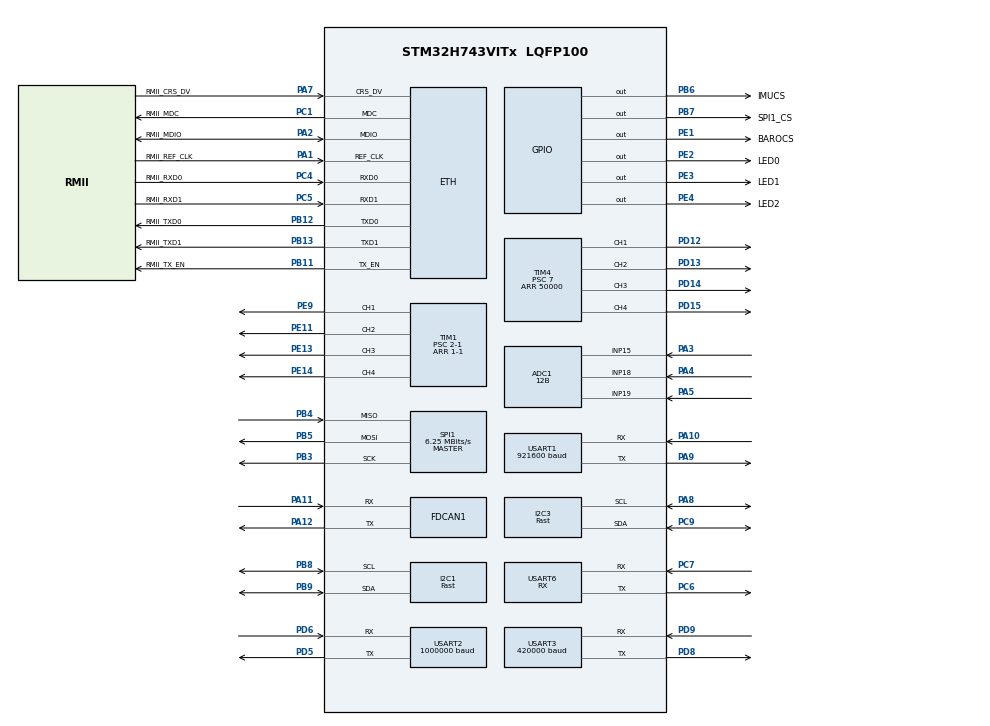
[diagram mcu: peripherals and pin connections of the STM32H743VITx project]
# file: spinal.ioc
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ADC1.Channel-3\#ChannelRegularConversion=ADC_CHANNEL_15
ADC1.NbrOfConversionFlag=1
ADC1.OffsetNumber-3\#ChannelRegularConversion=ADC_OFFSET_NONE
ADC1.OffsetSignedSaturation-3\#ChannelRegularConversion=DISABLE
ADC1.Rank-3\#ChannelRegularConversion=1
ADC1.Resolution=ADC_RESOLUTION_12B
ADC1.SamplingTime-3\#ChannelRegularConversion=ADC_SAMPLETIME_2CYCLES_5
ADC1.master=1
CORTEX_M7.AccessPermission-Cortex_Memory_Protection_Unit_Region0_Settings=MPU_REGION_FULL_ACCESS
CORTEX_M7.AccessPermission-Cortex_Memory_Protection_Unit_Region10_Settings=MPU_REGION_FULL_ACCESS
CORTEX_M7.AccessPermission-Cortex_Memory_Protection_Unit_Region11_Settings=MPU_REGION_FULL_ACCESS
CORTEX_M7.AccessPermission-Cortex_Memory_Protection_Unit_Region1_Settings=MPU_REGION_FULL_ACCESS
CORTEX_M7.AccessPermission-Cortex_Memory_Protection_Unit_Region2_Settings=MPU_REGION_FULL_ACCESS
CORTEX_M7.AccessPermission-Cortex_Memory_Protection_Unit_Region3_Settings=MPU_REGION_FULL_ACCESS
CORTEX_M7.AccessPermission-Cortex_Memory_Protection_Unit_Region4_Settings=MPU_REGION_FULL_ACCESS
CORTEX_M7.AccessPermission-Cortex_Memory_Protection_Unit_Region5_Settings=MPU_REGION_FULL_ACCESS
CORTEX_M7.AccessPermission-Cortex_Memory_Protection_Unit_Region6_Settings=MPU_REGION_FULL_ACCESS
CORTEX_M7.AccessPermission-Cortex_Memory_Protection_Unit_Region7_Settings=MPU_REGION_FULL_ACCESS
CORTEX_M7.AccessPermission-Cortex_Memory_Protection_Unit_Region8_Settings=MPU_REGION_FULL_ACCESS
CORTEX_M7.AccessPermission-Cortex_Memory_Protection_Unit_Region9_Settings=MPU_REGION_FULL_ACCESS
CORTEX_M7.BaseAddress-Cortex_Memory_Protection_Unit_Region0_Settings=0x24040000
CORTEX_M7.BaseAddress-Cortex_Memory_Protection_Unit_Region10_Settings=0x24045100
CORTEX_M7.BaseAddress-Cortex_Memory_Protection_Unit_Region11_Settings=0x24045180
CORTEX_M7.BaseAddress-Cortex_Memory_Protection_Unit_Region1_Settings=0x24040400
CORTEX_M7.BaseAddress-Cortex_Memory_Protection_Unit_Region2_Settings=0x24044400
CORTEX_M7.BaseAddress-Cortex_Memory_Protection_Unit_Region3_Settings=0x30040000
CORTEX_M7.BaseAddress-Cortex_Memory_Protection_Unit_Region4_Settings=0x30044000
CORTEX_M7.BaseAddress-Cortex_Memory_Protection_Unit_Region5_Settings=0x30040000
CORTEX_M7.BaseAddress-Cortex_Memory_Protection_Unit_Region6_Settings=0x24044800
CORTEX_M7.BaseAddress-Cortex_Memory_Protection_Unit_Region7_Settings=0x24044C00
CORTEX_M7.BaseAddress-Cortex_Memory_Protection_Unit_Region8_Settings=0x24045000
CORTEX_M7.BaseAddress-Cortex_Memory_Protection_Unit_Region9_Settings=0x24045080
CORTEX_M7.CPU_DCache=Enabled
CORTEX_M7.CPU_ICache=Enabled
CORTEX_M7.Enable-Cortex_Memory_Protection_Unit_Region0_Settings=MPU_REGION_ENABLE
CORTEX_M7.Enable-Cortex_Memory_Protection_Unit_Region10_Settings=MPU_REGION_ENABLE
CORTEX_M7.Enable-Cortex_Memory_Protection_Unit_Region11_Settings=MPU_REGION_ENABLE
CORTEX_M7.Enable-Cortex_Memory_Protection_Unit_Region1_Settings=MPU_REGION_ENABLE
CORTEX_M7.Enable-Cortex_Memory_Protection_Unit_Region2_Settings=MPU_REGION_ENABLE
CORTEX_M7.Enable-Cortex_Memory_Protection_Unit_Region3_Settings=MPU_REGION_ENABLE
CORTEX_M7.Enable-Cortex_Memory_Protection_Unit_Region4_Settings=MPU_REGION_ENABLE
CORTEX_M7.Enable-Cortex_Memory_Protection_Unit_Region5_Settings=MPU_REGION_ENABLE
CORTEX_M7.Enable-Cortex_Memory_Protection_Unit_Region6_Settings=MPU_REGION_ENABLE
CORTEX_M7.Enable-Cortex_Memory_Protection_Unit_Region7_Settings=MPU_REGION_ENABLE
CORTEX_M7.Enable-Cortex_Memory_Protection_Unit_Region8_Settings=MPU_REGION_ENABLE
CORTEX_M7.Enable-Cortex_Memory_Protection_Unit_Region9_Settings=MPU_REGION_ENABLE
CORTEX_M7.IsBufferable-Cortex_Memory_Protection_Unit_Region10_Settings=MPU_ACCESS_NOT_BUFFERABLE
CORTEX_M7.IsBufferable-Cortex_Memory_Protection_Unit_Region5_Settings=MPU_ACCESS_BUFFERABLE
CORTEX_M7.IsCacheable-Cortex_Memory_Protection_Unit_Region10_Settings=MPU_ACCESS_NOT_CACHEABLE
CORTEX_M7.IsCacheable-Cortex_Memory_Protection_Unit_Region1_Settings=MPU_ACCESS_CACHEABLE
CORTEX_M7.IsCacheable-Cortex_Memory_Protection_Unit_Region4_Settings=MPU_ACCESS_CACHEABLE
CORTEX_M7.IsShareable-Cortex_Memory_Protection_Unit_Region10_Settings=MPU_ACCESS_NOT_SHAREABLE
CORTEX_M7.IsShareable-Cortex_Memory_Protection_Unit_Region1_Settings=MPU_ACCESS_SHAREABLE
CORTEX_M7.MPU_Control=MPU_PRIVILEGED_DEFAULT
CORTEX_M7.Size-Cortex_Memory_Protection_Unit_Region0_Settings=MPU_REGION_SIZE_1KB
CORTEX_M7.Size-Cortex_Memory_Protection_Unit_Region10_Settings=MPU_REGION_SIZE_128B
CORTEX_M7.Size-Cortex_Memory_Protection_Unit_Region11_Settings=MPU_REGION_SIZE_128B
CORTEX_M7.Size-Cortex_Memory_Protection_Unit_Region1_Settings=MPU_REGION_SIZE_16KB
CORTEX_M7.Size-Cortex_Memory_Protection_Unit_Region2_Settings=MPU_REGION_SIZE_16KB
CORTEX_M7.Size-Cortex_Memory_Protection_Unit_Region3_Settings=MPU_REGION_SIZE_16KB
CORTEX_M7.Size-Cortex_Memory_Protection_Unit_Region4_Settings=MPU_REGION_SIZE_16KB
CORTEX_M7.Size-Cortex_Memory_Protection_Unit_Region5_Settings=MPU_REGION_SIZE_256B
CORTEX_M7.Size-Cortex_Memory_Protection_Unit_Region6_Settings=MPU_REGION_SIZE_1KB
CORTEX_M7.Size-Cortex_Memory_Protection_Unit_Region7_Settings=MPU_REGION_SIZE_1KB
CORTEX_M7.Size-Cortex_Memory_Protection_Unit_Region8_Settings=MPU_REGION_SIZE_128B
CORTEX_M7.Size-Cortex_Memory_Protection_Unit_Region9_Settings=MPU_REGION_SIZE_128B
CORTEX_M7.TypeExtField-Cortex_Memory_Protection_Unit_Region0_Settings=MPU_TEX_LEVEL1
CORTEX_M7.TypeExtField-Cortex_Memory_Protection_Unit_Region2_Settings=MPU_TEX_LEVEL1
CORTEX_M7.TypeExtField-Cortex_Memory_Protection_Unit_Region3_Settings=MPU_TEX_LEVEL1
CORTEX_M7.TypeExtField-Cortex_Memory_Protection_Unit_Region6_Settings=MPU_TEX_LEVEL1
CORTEX_M7.TypeExtField-Cortex_Memory_Protection_Unit_Region7_Settings=MPU_TEX_LEVEL1
Dma.Request0=USART1_RX
Dma.Request1=USART1_TX
Dma.Request2=USART3_RX
Dma.Request3=TIM1_CH1
Dma.Request4=TIM1_CH2
Dma.Request5=TIM1_CH3
Dma.Request6=TIM1_CH4
Dma.Request7=USART6_RX
Dma.Request8=USART2_RX
Dma.TIM1_CH1.3.Direction=DMA_MEMORY_TO_PERIPH
Dma.TIM1_CH1.3.EventEnable=DISABLE
Dma.TIM1_CH1.3.FIFOMode=DMA_FIFOMODE_ENABLE
Dma.TIM1_CH1.3.FIFOThreshold=DMA_FIFO_THRESHOLD_1QUARTERFULL
Dma.TIM1_CH1.3.Instance=DMA2_Stream0
Dma.TIM1_CH1.3.MemBurst=DMA_MBURST_SINGLE
Dma.TIM1_CH1.3.MemDataAlignment=DMA_MDATAALIGN_WORD
Dma.TIM1_CH1.3.MemInc=DMA_MINC_ENABLE
Dma.TIM1_CH1.3.Mode=DMA_NORMAL
Dma.TIM1_CH1.3.PeriphBurst=DMA_PBURST_SINGLE
Dma.TIM1_CH1.3.PeriphDataAlignment=DMA_PDATAALIGN_WORD
Dma.TIM1_CH1.3.PeriphInc=DMA_PINC_DISABLE
Dma.TIM1_CH1.3.Polarity=HAL_DMAMUX_REQ_GEN_RISING
Dma.TIM1_CH1.3.Priority=DMA_PRIORITY_HIGH
Dma.TIM1_CH1.3.RequestNumber=1
Dma.TIM1_CH1.3.SignalID=NONE
Dma.TIM1_CH1.3.SyncEnable=DISABLE
Dma.TIM1_CH1.3.SyncPolarity=HAL_DMAMUX_SYNC_NO_EVENT
Dma.TIM1_CH1.3.SyncRequestNumber=1
Dma.TIM1_CH1.3.SyncSignalID=NONE
Dma.TIM1_CH2.4.Direction=DMA_MEMORY_TO_PERIPH
Dma.TIM1_CH2.4.EventEnable=DISABLE
Dma.TIM1_CH2.4.FIFOMode=DMA_FIFOMODE_ENABLE
Dma.TIM1_CH2.4.FIFOThreshold=DMA_FIFO_THRESHOLD_1QUARTERFULL
Dma.TIM1_CH2.4.Instance=DMA2_Stream1
Dma.TIM1_CH2.4.MemBurst=DMA_MBURST_SINGLE
Dma.TIM1_CH2.4.MemDataAlignment=DMA_MDATAALIGN_WORD
Dma.TIM1_CH2.4.MemInc=DMA_MINC_ENABLE
Dma.TIM1_CH2.4.Mode=DMA_NORMAL
Dma.TIM1_CH2.4.PeriphBurst=DMA_PBURST_SINGLE
Dma.TIM1_CH2.4.PeriphDataAlignment=DMA_PDATAALIGN_WORD
Dma.TIM1_CH2.4.PeriphInc=DMA_PINC_DISABLE
Dma.TIM1_CH2.4.Polarity=HAL_DMAMUX_REQ_GEN_RISING
Dma.TIM1_CH2.4.Priority=DMA_PRIORITY_HIGH
Dma.TIM1_CH2.4.RequestNumber=1
Dma.TIM1_CH2.4.SignalID=NONE
Dma.TIM1_CH2.4.SyncEnable=DISABLE
Dma.TIM1_CH2.4.SyncPolarity=HAL_DMAMUX_SYNC_NO_EVENT
Dma.TIM1_CH2.4.SyncRequestNumber=1
Dma.TIM1_CH2.4.SyncSignalID=NONE
Dma.TIM1_CH3.5.Direction=DMA_MEMORY_TO_PERIPH
Dma.TIM1_CH3.5.EventEnable=DISABLE
Dma.TIM1_CH3.5.FIFOMode=DMA_FIFOMODE_ENABLE
Dma.TIM1_CH3.5.FIFOThreshold=DMA_FIFO_THRESHOLD_1QUARTERFULL
Dma.TIM1_CH3.5.Instance=DMA2_Stream2
Dma.TIM1_CH3.5.MemBurst=DMA_MBURST_SINGLE
Dma.TIM1_CH3.5.MemDataAlignment=DMA_MDATAALIGN_WORD
Dma.TIM1_CH3.5.MemInc=DMA_MINC_ENABLE
Dma.TIM1_CH3.5.Mode=DMA_NORMAL
Dma.TIM1_CH3.5.PeriphBurst=DMA_PBURST_SINGLE
Dma.TIM1_CH3.5.PeriphDataAlignment=DMA_PDATAALIGN_WORD
Dma.TIM1_CH3.5.PeriphInc=DMA_PINC_DISABLE
Dma.TIM1_CH3.5.Polarity=HAL_DMAMUX_REQ_GEN_RISING
Dma.TIM1_CH3.5.Priority=DMA_PRIORITY_HIGH
Dma.TIM1_CH3.5.RequestNumber=1
Dma.TIM1_CH3.5.SignalID=NONE
Dma.TIM1_CH3.5.SyncEnable=DISABLE
Dma.TIM1_CH3.5.SyncPolarity=HAL_DMAMUX_SYNC_NO_EVENT
Dma.TIM1_CH3.5.SyncRequestNumber=1
Dma.TIM1_CH3.5.SyncSignalID=NONE
Dma.TIM1_CH4.6.Direction=DMA_MEMORY_TO_PERIPH
Dma.TIM1_CH4.6.EventEnable=DISABLE
Dma.TIM1_CH4.6.FIFOMode=DMA_FIFOMODE_ENABLE
Dma.TIM1_CH4.6.FIFOThreshold=DMA_FIFO_THRESHOLD_1QUARTERFULL
Dma.TIM1_CH4.6.Instance=DMA2_Stream3
Dma.TIM1_CH4.6.MemBurst=DMA_MBURST_SINGLE
Dma.TIM1_CH4.6.MemDataAlignment=DMA_MDATAALIGN_WORD
Dma.TIM1_CH4.6.MemInc=DMA_MINC_ENABLE
Dma.TIM1_CH4.6.Mode=DMA_NORMAL
Dma.TIM1_CH4.6.PeriphBurst=DMA_PBURST_SINGLE
Dma.TIM1_CH4.6.PeriphDataAlignment=DMA_PDATAALIGN_WORD
Dma.TIM1_CH4.6.PeriphInc=DMA_PINC_DISABLE
Dma.TIM1_CH4.6.Polarity=HAL_DMAMUX_REQ_GEN_RISING
Dma.TIM1_CH4.6.Priority=DMA_PRIORITY_HIGH
Dma.TIM1_CH4.6.RequestNumber=1
Dma.TIM1_CH4.6.SignalID=NONE
Dma.TIM1_CH4.6.SyncEnable=DISABLE
Dma.TIM1_CH4.6.SyncPolarity=HAL_DMAMUX_SYNC_NO_EVENT
Dma.TIM1_CH4.6.SyncRequestNumber=1
Dma.TIM1_CH4.6.SyncSignalID=NONE
Dma.USART1_RX.0.Direction=DMA_PERIPH_TO_MEMORY
Dma.USART1_RX.0.EventEnable=DISABLE
Dma.USART1_RX.0.FIFOMode=DMA_FIFOMODE_DISABLE
Dma.USART1_RX.0.Instance=DMA1_Stream0
Dma.USART1_RX.0.MemDataAlignment=DMA_MDATAALIGN_BYTE
Dma.USART1_RX.0.MemInc=DMA_MINC_ENABLE
Dma.USART1_RX.0.Mode=DMA_CIRCULAR
Dma.USART1_RX.0.PeriphDataAlignment=DMA_PDATAALIGN_BYTE
Dma.USART1_RX.0.PeriphInc=DMA_PINC_DISABLE
Dma.USART1_RX.0.Polarity=HAL_DMAMUX_REQ_GEN_RISING
Dma.USART1_RX.0.Priority=DMA_PRIORITY_VERY_HIGH
Dma.USART1_RX.0.RequestNumber=1
Dma.USART1_RX.0.SignalID=NONE
Dma.USART1_RX.0.SyncEnable=DISABLE
Dma.USART1_RX.0.SyncPolarity=HAL_DMAMUX_SYNC_NO_EVENT
Dma.USART1_RX.0.SyncRequestNumber=1
Dma.USART1_RX.0.SyncSignalID=NONE
Dma.USART1_TX.1.Direction=DMA_MEMORY_TO_PERIPH
Dma.USART1_TX.1.EventEnable=DISABLE
Dma.USART1_TX.1.FIFOMode=DMA_FIFOMODE_DISABLE
Dma.USART1_TX.1.Instance=DMA1_Stream1
Dma.USART1_TX.1.MemDataAlignment=DMA_MDATAALIGN_BYTE
Dma.USART1_TX.1.MemInc=DMA_MINC_ENABLE
Dma.USART1_TX.1.Mode=DMA_NORMAL
Dma.USART1_TX.1.PeriphDataAlignment=DMA_PDATAALIGN_BYTE
Dma.USART1_TX.1.PeriphInc=DMA_PINC_DISABLE
Dma.USART1_TX.1.Polarity=HAL_DMAMUX_REQ_GEN_RISING
Dma.USART1_TX.1.Priority=DMA_PRIORITY_VERY_HIGH
Dma.USART1_TX.1.RequestNumber=1
Dma.USART1_TX.1.SignalID=NONE
Dma.USART1_TX.1.SyncEnable=DISABLE
Dma.USART1_TX.1.SyncPolarity=HAL_DMAMUX_SYNC_NO_EVENT
Dma.USART1_TX.1.SyncRequestNumber=1
Dma.USART1_TX.1.SyncSignalID=NONE
Dma.USART2_RX.8.Direction=DMA_PERIPH_TO_MEMORY
Dma.USART2_RX.8.EventEnable=DISABLE
Dma.USART2_RX.8.FIFOMode=DMA_FIFOMODE_DISABLE
Dma.USART2_RX.8.Instance=DMA1_Stream4
Dma.USART2_RX.8.MemDataAlignment=DMA_MDATAALIGN_BYTE
Dma.USART2_RX.8.MemInc=DMA_MINC_ENABLE
Dma.USART2_RX.8.Mode=DMA_CIRCULAR
Dma.USART2_RX.8.PeriphDataAlignment=DMA_PDATAALIGN_BYTE
Dma.USART2_RX.8.PeriphInc=DMA_PINC_DISABLE
Dma.USART2_RX.8.Polarity=HAL_DMAMUX_REQ_GEN_RISING
Dma.USART2_RX.8.Priority=DMA_PRIORITY_HIGH
Dma.USART2_RX.8.RequestNumber=1
Dma.USART2_RX.8.SignalID=NONE
Dma.USART2_RX.8.SyncEnable=DISABLE
Dma.USART2_RX.8.SyncPolarity=HAL_DMAMUX_SYNC_NO_EVENT
Dma.USART2_RX.8.SyncRequestNumber=1
Dma.USART2_RX.8.SyncSignalID=NONE
Dma.USART3_RX.2.Direction=DMA_PERIPH_TO_MEMORY
Dma.USART3_RX.2.EventEnable=DISABLE
Dma.USART3_RX.2.FIFOMode=DMA_FIFOMODE_DISABLE
Dma.USART3_RX.2.Instance=DMA1_Stream2
Dma.USART3_RX.2.MemDataAlignment=DMA_MDATAALIGN_BYTE
Dma.USART3_RX.2.MemInc=DMA_MINC_ENABLE
Dma.USART3_RX.2.Mode=DMA_CIRCULAR
Dma.USART3_RX.2.PeriphDataAlignment=DMA_PDATAALIGN_BYTE
Dma.USART3_RX.2.PeriphInc=DMA_PINC_DISABLE
Dma.USART3_RX.2.Polarity=HAL_DMAMUX_REQ_GEN_RISING
Dma.USART3_RX.2.Priority=DMA_PRIORITY_HIGH
Dma.USART3_RX.2.RequestNumber=1
Dma.USART3_RX.2.SignalID=NONE
Dma.USART3_RX.2.SyncEnable=DISABLE
Dma.USART3_RX.2.SyncPolarity=HAL_DMAMUX_SYNC_NO_EVENT
Dma.USART3_RX.2.SyncRequestNumber=1
Dma.USART3_RX.2.SyncSignalID=NONE
Dma.USART6_RX.7.Direction=DMA_PERIPH_TO_MEMORY
Dma.USART6_RX.7.EventEnable=DISABLE
Dma.USART6_RX.7.FIFOMode=DMA_FIFOMODE_DISABLE
Dma.USART6_RX.7.Instance=DMA1_Stream3
Dma.USART6_RX.7.MemDataAlignment=DMA_MDATAALIGN_BYTE
Dma.USART6_RX.7.MemInc=DMA_MINC_ENABLE
Dma.USART6_RX.7.Mode=DMA_CIRCULAR
Dma.USART6_RX.7.PeriphDataAlignment=DMA_PDATAALIGN_BYTE
Dma.USART6_RX.7.PeriphInc=DMA_PINC_DISABLE
Dma.USART6_RX.7.Polarity=HAL_DMAMUX_REQ_GEN_RISING
Dma.USART6_RX.7.Priority=DMA_PRIORITY_HIGH
Dma.USART6_RX.7.RequestNumber=1
Dma.USART6_RX.7.SignalID=NONE
Dma.USART6_RX.7.SyncEnable=DISABLE
Dma.USART6_RX.7.SyncPolarity=HAL_DMAMUX_SYNC_NO_EVENT
Dma.USART6_RX.7.SyncRequestNumber=1
Dma.USART6_RX.7.SyncSignalID=NONE
ETH.MediaInterface=HAL_ETH_RMII_MODE
FDCAN1.AutoRetransmission=ENABLE
FDCAN1.DataSyncJumpWidth=2
FDCAN1.DataTimeSeg1=7
FDCAN1.DataTimeSeg2=2
FDCAN1.FrameFormat=FDCAN_FRAME_FD_BRS
FDCAN1.MessageRAMOffset=0
FDCAN1.Mode=FDCAN_MODE_NORMAL
FDCAN1.NominalSyncJumpWidth=16
FDCAN1.NominalTimeSeg1=63
FDCAN1.NominalTimeSeg2=16
FDCAN1.RxFifo0ElmtSize=FDCAN_DATA_BYTES_64
FDCAN1.RxFifo0ElmtsNbr=1
FDCAN1.StdFiltersNbr=1
FDCAN1.TxElmtSize=FDCAN_DATA_BYTES_64
FDCAN1.TxFifoQueueElmtsNbr=10
FREERTOS.BinarySemaphores01=coreTaskSem,Dynamic,NULL;uartTxSem,Dynamic,NULL
FREERTOS.Mutexes01=rosPubMutex,Dynamic,NULL;flightControlMutex,Dynamic,NULL
FREERTOS.Tasks01=coreTask,3,1024,coreTaskFunc,Default,NULL,Dynamic,NULL,NULL;rosSpinTask,0,1024,rosSpinTaskFunc,Default,NULL,Dynamic,NULL,NULL;idleTask,-3,128,idleTaskFunc,Default,NULL,Dynamic,NULL,NULL;imuPublishTask,0,1024,imuPublishTaskFunc,Default,NULL,Dynamic,NULL,NULL;voltage,0,256,voltageTask,Default,NULL,Dynamic,NULL,NULL;canRx,3,256,canRxTask,As weak,NULL,Dynamic,NULL,NULL;servoTask,3,256,ServoTaskCallback,As weak,NULL,Dynamic,NULL,NULL
FREERTOS.Timers01=coreTaskTimer,coreTaskEvokeCb,osTimerPeriodic,Default,NULL,Dynamic,NULL
FREERTOS.configTIMER_TASK_PRIORITY=6
FREERTOS.configTOTAL_HEAP_SIZE=25600
FREERTOS.configUSE_TIMERS=1
I2C1.I2C_Speed_Mode=I2C_Fast
I2C1.Timing=0x009034B6
I2C3.I2C_Speed_Mode=I2C_Fast
I2C3.Timing=0x009034B6
LWIP.BSP.number=1
LWIP.GATEWAY_ADDRESS=192.168.025.253
LWIP.IP_ADDRESS=192.168.025.238
LWIP.LWIP_DHCP=0
LWIP.NETMASK_ADDRESS=255.255.255.000
LWIP.Version=v2.1.2_Cube
LWIP0.BSP.STBoard=false
LWIP0.BSP.api=BSP_COMPONENT_DRIVER
LWIP0.BSP.component=LAN8742
LWIP0.BSP.i2caddr=0
LWIP0.BSP.instance=LAN8742
LWIP0.BSP.name=Driver_PHY
LWIP0.BSP.solution=LAN8742
Mcu.Family=STM32H7
Mcu.Name=STM32H743VITx
Mcu.Package=LQFP100
NVIC.DMA1_Stream0_IRQn=true\:5\:0\:false\:false\:true\:true\:false\:true
NVIC.DMA1_Stream1_IRQn=true\:5\:0\:false\:false\:true\:true\:false\:true
NVIC.DMA1_Stream2_IRQn=true\:5\:0\:false\:false\:true\:true\:false\:true
NVIC.DMA1_Stream3_IRQn=true\:5\:0\:false\:false\:true\:true\:false\:true
NVIC.DMA1_Stream4_IRQn=true\:5\:0\:false\:false\:true\:true\:false\:true
NVIC.DMA2_Stream0_IRQn=true\:5\:0\:false\:false\:true\:true\:false\:true
NVIC.DMA2_Stream1_IRQn=true\:5\:0\:false\:false\:true\:false\:false\:true
NVIC.DMA2_Stream2_IRQn=true\:5\:0\:false\:false\:true\:false\:false\:true
NVIC.DMA2_Stream3_IRQn=true\:5\:0\:false\:false\:true\:false\:false\:true
NVIC.ETH_IRQn=true\:5\:0\:false\:false\:true\:true\:true\:true
NVIC.ETH_WKUP_IRQn=true\:5\:0\:false\:false\:true\:true\:true\:true
NVIC.FDCAN1_IT0_IRQn=true\:5\:0\:false\:false\:true\:true\:true\:true
NVIC.PriorityGroup=NVIC_PRIORITYGROUP_4
NVIC.TIM8_BRK_TIM12_IRQn=true\:0\:0\:false\:false\:true\:false\:false\:true
NVIC.TimeBase=TIM8_BRK_TIM12_IRQn
NVIC.TimeBaseIP=TIM12
NVIC.USART1_IRQn=true\:5\:0\:false\:false\:true\:true\:true\:true
PA1.GPIO_Label=RMII_REF_CLK
PA1.GPIO_Speed=GPIO_SPEED_FREQ_VERY_HIGH
PA1.Mode=RMII
PA1.Signal=ETH_REF_CLK
PA10.Mode=Asynchronous
PA10.Signal=USART1_RX
PA11.Mode=FDCAN_Activate
PA11.Signal=FDCAN1_RX
PA12.Mode=FDCAN_Activate
PA12.Signal=FDCAN1_TX
PA13\ (JTMS/SWDIO).Mode=Serial_Wire
PA13\ (JTMS/SWDIO).Signal=DEBUG_JTMS-SWDIO
PA14\ (JTCK/SWCLK).Mode=Serial_Wire
PA14\ (JTCK/SWCLK).Signal=DEBUG_JTCK-SWCLK
PA2.GPIO_Label=RMII_MDIO
PA2.GPIO_Speed=GPIO_SPEED_FREQ_VERY_HIGH
PA2.Mode=RMII
PA2.Signal=ETH_MDIO
PA3.Signal=ADCx_INP15
PA4.Signal=ADCx_INP18
PA5.Signal=ADCx_INP19
PA7.GPIO_Label=RMII_CRS_DV
PA7.GPIO_Speed=GPIO_SPEED_FREQ_VERY_HIGH
PA7.Mode=RMII
PA7.Signal=ETH_CRS_DV
PA8.Mode=I2C
PA8.Signal=I2C3_SCL
PA9.Mode=Asynchronous
PA9.Signal=USART1_TX
PB11.GPIO_Label=RMII_TX_EN
PB11.GPIO_Speed=GPIO_SPEED_FREQ_VERY_HIGH
PB11.Mode=RMII
PB11.Signal=ETH_TX_EN
PB12.GPIO_Label=RMII_TXD0
PB12.GPIO_Speed=GPIO_SPEED_FREQ_VERY_HIGH
PB12.Mode=RMII
PB12.Signal=ETH_TXD0
PB13.GPIO_Label=RMII_TXD1
PB13.GPIO_Speed=GPIO_SPEED_FREQ_VERY_HIGH
PB13.Mode=RMII
PB13.Signal=ETH_TXD1
PB3\ (JTDO/TRACESWO).GPIO_Speed=GPIO_SPEED_FREQ_VERY_HIGH
PB3\ (JTDO/TRACESWO).Mode=Full_Duplex_Master
PB3\ (JTDO/TRACESWO).Signal=SPI1_SCK
PB4\ (NJTRST).GPIO_Speed=GPIO_SPEED_FREQ_VERY_HIGH
PB4\ (NJTRST).Mode=Full_Duplex_Master
PB4\ (NJTRST).Signal=SPI1_MISO
PB5.GPIO_Speed=GPIO_SPEED_FREQ_VERY_HIGH
PB5.Mode=Full_Duplex_Master
PB5.Signal=SPI1_MOSI
PB6.GPIO_FM6=__NULL
PB6.GPIO_Label=IMUCS
PB6.GPIO_Speed=GPIO_SPEED_FREQ_MEDIUM
PB6.PinState=GPIO_PIN_SET
PB6.Signal=GPIO_Output
PB7.GPIO_Label=SPI1_CS
PB7.GPIO_Speed=GPIO_SPEED_FREQ_HIGH
PB7.PinState=GPIO_PIN_SET
PB7.Signal=GPIO_Output
PB8.Mode=I2C
PB8.Signal=I2C1_SCL
PB9.Mode=I2C
PB9.Signal=I2C1_SDA
PC1.GPIO_Label=RMII_MDC
PC1.Mode=RMII
PC1.Signal=ETH_MDC
PC4.GPIO_Label=RMII_RXD0
PC4.GPIO_Speed=GPIO_SPEED_FREQ_VERY_HIGH
PC4.Mode=RMII
PC4.Signal=ETH_RXD0
PC5.GPIO_Label=RMII_RXD1
PC5.GPIO_Speed=GPIO_SPEED_FREQ_VERY_HIGH
PC5.Mode=RMII
PC5.Signal=ETH_RXD1
PC6.Mode=Asynchronous
PC6.Signal=USART6_TX
PC7.Mode=Asynchronous
PC7.Signal=USART6_RX
PC9.Mode=I2C
PC9.Signal=I2C3_SDA
PD12.Signal=S_TIM4_CH1
PD13.Signal=S_TIM4_CH2
PD14.Signal=S_TIM4_CH3
PD15.Signal=S_TIM4_CH4
PD5.GPIO_ModeDefaultOD=GPIO_MODE_AF_PP
PD5.GPIO_PuPd=GPIO_NOPULL
PD5.GPIO_Speed=GPIO_SPEED_FREQ_VERY_HIGH
PD5.Mode=Asynchronous
PD5.Signal=USART2_TX
PD6.Mode=Asynchronous
PD6.Signal=USART2_RX
PD8.GPIO_ModeDefaultOD=GPIO_MODE_AF_PP
PD8.GPIO_PuPd=GPIO_NOPULL
PD8.GPIO_Speed=GPIO_SPEED_FREQ_VERY_HIGH
PD8.Mode=Asynchronous
PD8.Signal=USART3_TX
PD9.Mode=Asynchronous
PD9.Signal=USART3_RX
PE1.GPIO_Label=BAROCS
PE1.Signal=GPIO_Output
PE11.Signal=S_TIM1_CH2
PE13.Signal=S_TIM1_CH3
PE14.Signal=S_TIM1_CH4
PE2.GPIO_Label=LED0
PE2.GPIO_ModeDefaultOutputPP=GPIO_MODE_OUTPUT_OD
PE2.GPIO_Speed=GPIO_SPEED_FREQ_MEDIUM
PE2.Signal=GPIO_Output
PE3.GPIO_Label=LED1
PE3.GPIO_ModeDefaultOutputPP=GPIO_MODE_OUTPUT_OD
PE3.GPIO_PuPd=GPIO_NOPULL
PE3.GPIO_Speed=GPIO_SPEED_FREQ_MEDIUM
PE3.Signal=GPIO_Output
PE4.GPIO_Label=LED2
PE4.GPIO_ModeDefaultOutputPP=GPIO_MODE_OUTPUT_OD
PE4.GPIO_Speed=GPIO_SPEED_FREQ_MEDIUM
PE4.Signal=GPIO_Output
PE9.Signal=S_TIM1_CH1
PH0-OSC_IN\ (PH0).Mode=HSE-External-Oscillator
PH0-OSC_IN\ (PH0).Signal=RCC_OSC_IN
PH1-OSC_OUT\ (PH1).Mode=HSE-External-Oscillator
PH1-OSC_OUT\ (PH1).Signal=RCC_OSC_OUT
ProjectManager.HeapSize=0x2000
ProjectManager.StackSize=0x4000
ProjectManager.TargetToolchain=STM32CubeIDE
RCC.ADCFreq_Value=400000000
RCC.APB1Freq_Value=100000000
RCC.APB2Freq_Value=100000000
RCC.APB3Freq_Value=100000000
RCC.APB4Freq_Value=100000000
RCC.CortexFreq_Value=400000000
RCC.D1PPRE=RCC_APB3_DIV2
RCC.D2PPRE1=RCC_APB1_DIV2
RCC.D2PPRE2=RCC_APB2_DIV2
RCC.D3PPRE=RCC_APB4_DIV2
RCC.DIVM1=1
RCC.DIVM2=1
RCC.DIVM3=1
RCC.DIVN1=100
RCC.DIVN2=100
RCC.DIVN3=100
RCC.DIVQ1=4
RCC.DIVQ2=10
RCC.FDCANCLockSelection=RCC_FDCANCLKSOURCE_PLL2
RCC.HCLKFreq_Value=200000000
RCC.HPRE=RCC_HCLK_DIV2
RCC.HSE_VALUE=8000000
RCC.PLL2FRACN=0
RCC.PLL3FRACN=0
RCC.PLLFRACN=0
RCC.PLLSourceVirtual=RCC_PLLSOURCE_HSE
RCC.PWR_Regulator_Voltage_Scale=PWR_REGULATOR_VOLTAGE_SCALE1
RCC.SYSCLKFreq_VALUE=400000000
RCC.SYSCLKSource=RCC_SYSCLKSOURCE_PLLCLK
RCC.USBFreq_Value=200000000
SH.ADCx_INP15.0=ADC1_INP15,IN15-Single-Ended
SH.ADCx_INP18.0=ADC1_INP18,IN18-Single-Ended
SH.ADCx_INP19.0=ADC1_INP19,IN19-Single-Ended
SH.S_TIM1_CH1.0=TIM1_CH1,PWM Generation1 CH1
SH.S_TIM1_CH2.0=TIM1_CH2,PWM Generation2 CH2
SH.S_TIM1_CH3.0=TIM1_CH3,PWM Generation3 CH3
SH.S_TIM1_CH4.0=TIM1_CH4,PWM Generation4 CH4
SH.S_TIM4_CH1.0=TIM4_CH1,PWM Generation1 CH1
SH.S_TIM4_CH2.0=TIM4_CH2,PWM Generation2 CH2
SH.S_TIM4_CH3.0=TIM4_CH3,PWM Generation3 CH3
SH.S_TIM4_CH4.0=TIM4_CH4,PWM Generation4 CH4
SPI1.BaudRatePrescaler=SPI_BAUDRATEPRESCALER_32
SPI1.CLKPhase=SPI_PHASE_2EDGE
SPI1.CLKPolarity=SPI_POLARITY_HIGH
SPI1.CalculateBaudRate=6.25 MBits/s
SPI1.DataSize=SPI_DATASIZE_8BIT
SPI1.Direction=SPI_DIRECTION_2LINES
SPI1.Mode=SPI_MODE_MASTER
SPI1.VirtualType=VM_MASTER
TIM1.Channel-PWM\ Generation1\ CH1=TIM_CHANNEL_1
TIM1.Channel-PWM\ Generation2\ CH2=TIM_CHANNEL_2
TIM1.Channel-PWM\ Generation3\ CH3=TIM_CHANNEL_3
TIM1.Channel-PWM\ Generation4\ CH4=TIM_CHANNEL_4
TIM1.CounterMode=TIM_COUNTERMODE_UP
TIM1.Period=1-1
TIM1.Prescaler=2-1
TIM1.Pulse-PWM\ Generation1\ CH1=0
TIM4.Channel-PWM\ Generation1\ CH1=TIM_CHANNEL_1
TIM4.Channel-PWM\ Generation2\ CH2=TIM_CHANNEL_2
TIM4.Channel-PWM\ Generation3\ CH3=TIM_CHANNEL_3
TIM4.Channel-PWM\ Generation4\ CH4=TIM_CHANNEL_4
TIM4.Period=50000
TIM4.Prescaler=7
TIM4.Pulse-PWM\ Generation1\ CH1=10000
TIM4.Pulse-PWM\ Generation2\ CH2=10000
TIM4.Pulse-PWM\ Generation3\ CH3=10000
TIM4.Pulse-PWM\ Generation4\ CH4=10000
USART1.BaudRate=921600
USART1.VirtualMode-Asynchronous=VM_ASYNC
USART2.BaudRate=1000000
USART2.Parity=PARITY_NONE
USART2.VirtualMode-Asynchronous=VM_ASYNC
USART2.WordLength=WORDLENGTH_8B
USART3.BaudRate=420000
USART3.Parity=PARITY_NONE
USART3.VirtualMode-Asynchronous=VM_ASYNC
USART3.WordLength=WORDLENGTH_8B
USART6.Mode=MODE_RX
USART6.VirtualMode=VM_ASYNC
VP_FREERTOS_VS_CMSIS_V1.Mode=CMSIS_V1
VP_LWIP_VS_Enabled.Mode=Enabled
VP_SYS_VS_tim12.Mode=TIM12
VP_TIM1_VS_ClockSourceINT.Mode=Internal
VP_TIM4_VS_ClockSourceINT.Mode=Internal
board=custom

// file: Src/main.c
/* USER CODE BEGIN Header */
/**
  ******************************************************************************
  * @file           : main.c
  * @brief          : Main program body
  ******************************************************************************
  * @attention
  *
  * <h2><center>&copy; Copyright (c) 2021 STMicroelectronics.
  * All rights reserved.</center></h2>
  *
  * This software component is licensed by ST under BSD 3-Clause license,
  * the "License"; You may not use this file except in compliance with the
  * License. You may obtain a copy of the License at:
  *                        opensource.org/licenses/BSD-3-Clause
  *
  ******************************************************************************
  */
/* USER CODE END Header */
#include "main.h"
#include "cmsis_os.h"
#include "lwip.h"

/* USER CODE BEGIN Includes */

#include <cstring>
#include <string>

#include "communication/spinal_link_xrce_adapter.h"
#include "xrce_dds/xrce_dds_client.h"
#include "flashmemory/application_capabilities.h"
#include "flashmemory/config_flash_database.h"
#include "flashmemory/config_flash_storage.h"
#include "flashmemory/flashmemory.h"
#include "sensors/imu/drivers/mpu9250/imu_mpu9250.h"
#include "sensors/imu/drivers/icm20948/icm_20948.h"
#include "sensors/baro/baro_ms5611.h"
#include "sensors/gps/gps_ublox.h"
#include "rc/crsf_input.h"
#include "rc/crsf_stm32_uart_transport.h"

#include "battery_status/battery_status.h"
#include "servo/servo.h"
#include "thruster/board/thruster_manager.h"
#include "flight_control/flight_control.h"
#include "bootloader/system_bootloader.h"

#include "state_estimate/state_estimate.h"

/* #include <Spine/spine.h> */

/* #include "dshot_esc/dshot.h" */

/* USER CODE END Includes */

ADC_HandleTypeDef hadc1;

FDCAN_HandleTypeDef hfdcan1;

I2C_HandleTypeDef hi2c1;
I2C_HandleTypeDef hi2c3;

SPI_HandleTypeDef hspi1;

TIM_HandleTypeDef htim1;
TIM_HandleTypeDef htim4;
DMA_HandleTypeDef hdma_tim1_ch1;
DMA_HandleTypeDef hdma_tim1_ch2;
DMA_HandleTypeDef hdma_tim1_ch3;
DMA_HandleTypeDef hdma_tim1_ch4;

UART_HandleTypeDef huart1;
UART_HandleTypeDef huart2;
UART_HandleTypeDef huart3;
UART_HandleTypeDef huart6;
DMA_HandleTypeDef hdma_usart1_rx;
DMA_HandleTypeDef hdma_usart1_tx;
DMA_HandleTypeDef hdma_usart2_rx;
DMA_HandleTypeDef hdma_usart3_rx;
DMA_HandleTypeDef hdma_usart6_rx;

osThreadId coreTaskHandle;
osThreadId communicationTaskHandle;
osThreadId idleTaskHandle;
osThreadId imuPublishTaskHandle;
osThreadId voltageHandle;
osThreadId canRxHandle;
osThreadId servoTaskHandle;
osTimerId coreTaskTimerHandle;
osMutexId rosPubMutexHandle;
osMutexId flightControlMutexHandle;
osSemaphoreId coreTaskSemHandle;
osSemaphoreId uartTxSemHandle;
/* USER CODE BEGIN PV */
osMailQId canMsgMailHandle;

ConfigFlashPayload g_boot_config = ApplicationCapability::defaults();
uint8_t g_uart3_driver = DEFAULT_UART3_DRIVER;
ConfigFlashDatabase config_flash_database_;

/* /\* sensor instances *\/ */
IMUOnboard mpu9250_imu_;
ICM20948 icm20948_imu_;
IMU* imu_ = nullptr;

Baro baro_;
GPS gps_;
CrsfStm32UartTransport crsf_transport_;
CrsfFlightControlSink crsf_control_sink_;
CrsfInput crsf_input_;
BatteryStatus battery_status_;
ThrusterManager thruster_;
FlightControl flight_control_;

/* servo instance */
DirectServo servo_;
/* DShot dshot_; */

StateEstimate estimator_;
XrceDdsClient xrce_client_;
SpinalLinkXrceAdapter spinal_link_xrce_adapter_;

/* USER CODE END PV */

void SystemClock_Config(void);
static void MPU_Config(void);
static void MX_GPIO_Init(void);
static void MX_DMA_Init(void);
static void MX_FDCAN1_Init(void);
static void MX_I2C1_Init(void);
static void MX_SPI1_Init(void);
static void MX_ADC1_Init(void);
static void MX_I2C3_Init(void);
static void MX_USART1_UART_Init(void);
static void MX_USART3_UART_Init(void);
static void MX_TIM1_Init(void);
static void MX_TIM4_Init(void);
static void MX_USART6_UART_Init(void);
static void MX_USART2_UART_Init(void);
void coreTaskFunc(void const * argument);
void communicationTaskFunc(void const * argument);
void idleTaskFunc(void const * argument);
void imuPublishTaskFunc(void const * argument);
void voltageTask(void const * argument);
void canRxTask(void const * argument);
void ServoTaskCallback(void const * argument);
void coreTaskEvokeCb(void const * argument);

int main(void)
{

  /* MPU Configuration--------------------------------------------------------*/
  MPU_Config();

  /* Enable I-Cache---------------------------------------------------------*/
  SCB_EnableICache();

  /* Enable D-Cache---------------------------------------------------------*/
  SCB_EnableDCache();

  /* MCU Configuration--------------------------------------------------------*/

  /* Reset of all peripherals, Initializes the Flash interface and the Systick. */
  HAL_Init();

  /* USER CODE BEGIN Init */

  SystemBootloader::restore_application_boot_address();

  /* USER CODE END Init */

  /* Configure the system clock */
  SystemClock_Config();

  if (!ConfigFlashStorage::load(config_flash_database_))
  {
    config_flash_database_.loadDefaults(ApplicationCapability::defaults());
  }
  g_boot_config = config_flash_database_.activeConfiguration();
  if (!ConfigFlashDatabase::validateConfiguration(g_boot_config, ApplicationCapability::support()))
  {
    g_boot_config = ApplicationCapability::defaults();
  }
  g_uart3_driver = g_boot_config.uart3_driver;
  config_flash_database_.setAppliedConfiguration(g_boot_config);

  /* Initialize all configured peripherals */
  MX_GPIO_Init();
  MX_DMA_Init();
  MX_FDCAN1_Init();
  MX_I2C1_Init();
  MX_SPI1_Init();
  MX_ADC1_Init();
  MX_I2C3_Init();
  MX_USART1_UART_Init();
  if (g_uart3_driver != Uart3Driver::DISABLED) MX_USART3_UART_Init();
  MX_TIM1_Init();
  MX_TIM4_Init();
  MX_USART6_UART_Init();
  MX_USART2_UART_Init();
  /* USER CODE BEGIN 2 */

  // workaround for the wired generation of STMCubeMX
  HAL_NVIC_DisableIRQ(DMA1_Stream0_IRQn); // we do not need DMA Interrupt for USART1 RX, circular mode
  HAL_NVIC_DisableIRQ(DMA1_Stream2_IRQn); // we do not need DMA Interrupt for USART3 RX, circular mode

  /* Flash Memory */
  FlashMemory::init(0x081E0000, FLASH_SECTOR_7);
  // Bank2, Sector7: 0x081E 0000 (128KB); https://www.stmcu.jp/download/?dlid=51599_jp
  // BANK1 (with Sector7) cuases the flash failure by STLink from the second time. So we use BANK_2, which is tested OK

  // It semms like the first 64 byte of flashmemory for data is easily to be overwritten by zero, when re-flash the flash memory.
  // A possible reason is the power supply from stlink does not contain 3.3V output.
  // which is the only difference compared with the old version (STM32F7)
  // So, we introduce following dummy data for a workaround to avoid the vanishment of stored data in flash memory.
  uint8_t dummy_data[64];
  memset(dummy_data, 1, 64);
  FlashMemory::addValue(dummy_data, 64);

#if 0 // test flash memory

  uint8_t test_data[128];
  for(int i = 0; i < 128; i++)
    test_data[i] = i;
  FlashMemory::addValue(test_data, 128);

  int32_t test_int = -1234;
  //int32_t test_int;
  FlashMemory::addValue(&test_int, sizeof(test_int));

  float test_float = 1.1f;
  //float test_float;
  FlashMemory::addValue(&test_float, sizeof(test_float));

  /* FlashMemory::erase(); */
  /* FlashMemory::write(); */
  FlashMemory::read();
#endif

  if (g_boot_config.imu_driver == ImuDriver::MPU9250)
  {
    mpu9250_imu_.init(&hspi1, &hi2c3, IMUCS_GPIO_Port, IMUCS_Pin, LED0_GPIO_Port, LED0_Pin);
    imu_ = &mpu9250_imu_;
  }
  else if (g_boot_config.imu_driver == ImuDriver::ICM20948)
  {
    icm20948_imu_.init(&hspi1, &hi2c3, IMUCS_GPIO_Port, IMUCS_Pin, LED0_GPIO_Port, LED0_Pin);
    imu_ = &icm20948_imu_;
  }
  Baro* selected_baro = nullptr;
  if (g_boot_config.barometer_enabled != 0U)
  {
    baro_.init_hw(&hi2c1, BAROCS_GPIO_Port, BAROCS_Pin);
    selected_baro = &baro_;
  }

  GPS* selected_gps = nullptr;

  if (g_uart3_driver == Uart3Driver::GPS)
  {
    gps_.init(&huart3, LED2_GPIO_Port, LED2_Pin);
    selected_gps = &gps_;
  }
  else if (g_uart3_driver == Uart3Driver::CRSF)
  {
    crsf_transport_.init(&huart3);
  }
  estimator_.init(imu_, selected_baro, selected_gps, g_boot_config.attitude_estimation_enabled != 0U,
                  g_boot_config.height_estimation_enabled != 0U,
                  g_boot_config.position_estimation_enabled != 0U);

/*   DShot* dshotptr = nullptr; */
  battery_status_.init(&hadc1, g_boot_config.motor_output_driver != MotorOutputDriver::DRIVER_DSHOT);

  thruster_.init(&htim1, &htim4, g_boot_config.motor_output_driver);
  if (g_boot_config.motor_output_driver == MotorOutputDriver::DRIVER_DSHOT)
    thruster_.initDShotTelemetry(&huart6);
  thruster_.setBatteryStatus(&battery_status_);

/* #if DSHOT */
  /* estimator_.init(&imu_, &baro_, &gps_, &node, &executor);  // imu + baro + gps => att + alt + pos(xy) */
/*   dshot_.init(DSHOT600, &htim1,TIM_CHANNEL_1, &htim1,TIM_CHANNEL_2, &htim1,TIM_CHANNEL_3, &htim1, TIM_CHANNEL_4); */
/*   dshot_.initTelemetry(&huart6); */
/*   dshotptr = &dshot_; */
/* #else */
/*   estimator_.init(&imu_, &baro_, &gps_, &nh_);  // imu + baro + gps => att + alt + pos(xy) */
/* #endif */

  FlashMemory::read(); // battery scale and IMU calib data (including IMU in neurons)

  const bool servo_connect = servo_.init(&huart2, nullptr, g_boot_config.servo_driver);

  // Keep the legacy calibration/servo layout intact and append the versioned
  // flight parameter image after every previously registered flash value.
  FlashMemory::addValue(
    flight_control_.parameterStorageData(),
    flight_control_.parameterStorageSize());
  FlashMemory::read();

  flight_control_.init(&estimator_, &thruster_, servo_connect ? &servo_ : nullptr);
  flight_control_.setEnabled(g_boot_config.flight_control_enabled != 0U);
  if (g_uart3_driver == Uart3Driver::CRSF)
  {
    crsf_control_sink_.init(&flight_control_);
    crsf_input_.init(&crsf_transport_, &crsf_control_sink_);
    crsf_input_.setEnabled(true);
  }

/*   bool nerve_connect = Spine::init(&hfdcan1, &nh_, &estimator_, &controller_, LED1_GPIO_Port, LED1_Pin); */

/*   if(nerve_connect) Spine::useRTOS(&canMsgMailHandle); // use RTOS for CAN in spianl */

  /* USER CODE END 2 */

  /* Create the mutex(es) */
  /* definition and creation of rosPubMutex */
  osMutexDef(rosPubMutex);
  rosPubMutexHandle = osMutexCreate(osMutex(rosPubMutex));

  /* definition and creation of flightControlMutex */
  osMutexDef(flightControlMutex);
  flightControlMutexHandle = osMutexCreate(osMutex(flightControlMutex));

  /* Create the semaphores(s) */
  /* definition and creation of coreTaskSem */
  osSemaphoreDef(coreTaskSem);
  coreTaskSemHandle = osSemaphoreCreate(osSemaphore(coreTaskSem), 1);

  /* definition and creation of uartTxSem */
  osSemaphoreDef(uartTxSem);
  uartTxSemHandle = osSemaphoreCreate(osSemaphore(uartTxSem), 1);

  xrce_client_.configure(&huart1, &rosPubMutexHandle, &uartTxSemHandle);
  spinal_link_xrce_adapter_.init(&xrce_client_, &estimator_, &flight_control_, &battery_status_,
                             g_uart3_driver == Uart3Driver::CRSF ? &crsf_input_ : nullptr,
                             &thruster_, &config_flash_database_,
                             &flightControlMutexHandle);

  /* Create the timer(s) */
  /* definition and creation of coreTaskTimer */
  osTimerDef(coreTaskTimer, coreTaskEvokeCb);
  coreTaskTimerHandle = osTimerCreate(osTimer(coreTaskTimer), osTimerPeriodic, NULL);

  /* USER CODE BEGIN RTOS_QUEUES */
  /* add queues, ... */
  /* add mail queue for CAN RX */
  /* osMailQDef(CanMail, 10, can_msg); // defualt: 20 for 8 data bytes (in case of initializer sendBoardConfig (4 servo: 1 + 4 x 3 = 13 packets)); 10 for 64 data bytes */
  /* canMsgMailHandle = osMailCreate(osMailQ(CanMail), NULL); */

  /* USER CODE END RTOS_QUEUES */

  /* Create the thread(s) */
  /* definition and creation of coreTask */
  osThreadDef(coreTask, coreTaskFunc, osPriorityRealtime, 0, 1024);
  coreTaskHandle = osThreadCreate(osThread(coreTask), NULL);

  /* Definition and creation of the direct XRCE-DDS communication task. */
  osThreadDef(communicationTask, communicationTaskFunc, osPriorityNormal, 0, 2048);
  communicationTaskHandle = osThreadCreate(osThread(communicationTask), NULL);

  /* definition and creation of idleTask */
  osThreadDef(idleTask, idleTaskFunc, osPriorityIdle, 0, 128);
  idleTaskHandle = osThreadCreate(osThread(idleTask), NULL);

  /* definition and creation of voltage */
  osThreadDef(voltage, voltageTask, osPriorityNormal, 0, 256);
  voltageHandle = osThreadCreate(osThread(voltage), NULL);

  /* definition and creation of canRx */
  osThreadDef(canRx, canRxTask, osPriorityRealtime, 0, 256);
  canRxHandle = osThreadCreate(osThread(canRx), NULL);

  /* definition and creation of servoTask */
  osThreadDef(servoTask, ServoTaskCallback, osPriorityRealtime, 0, 256);
  servoTaskHandle = osThreadCreate(osThread(servoTask), NULL);

  /* Start scheduler */
  osKernelStart();

  /* We should never get here as control is now taken by the scheduler */
  /* Infinite loop */
  while (1)
  {

    /* USER CODE BEGIN 3 */
    HAL_GPIO_TogglePin(LED0_GPIO_Port, LED0_Pin);
    HAL_GPIO_TogglePin(LED1_GPIO_Port, LED1_Pin);
    HAL_GPIO_TogglePin(LED2_GPIO_Port, LED2_Pin);
    HAL_Delay(1000);
  }
  /* USER CODE END 3 */
}

void SystemClock_Config(void)
{
  RCC_OscInitTypeDef RCC_OscInitStruct = {0};
  RCC_ClkInitTypeDef RCC_ClkInitStruct = {0};
  RCC_PeriphCLKInitTypeDef PeriphClkInitStruct = {0};

  /** Supply configuration update enable
  */
  HAL_PWREx_ConfigSupply(PWR_LDO_SUPPLY);
  /** Configure the main internal regulator output voltage
  */
  __HAL_PWR_VOLTAGESCALING_CONFIG(PWR_REGULATOR_VOLTAGE_SCALE1);

  while(!__HAL_PWR_GET_FLAG(PWR_FLAG_VOSRDY)) {}
  /** Macro to configure the PLL clock source
  */
  __HAL_RCC_PLL_PLLSOURCE_CONFIG(RCC_PLLSOURCE_HSE);
  /** Initializes the RCC Oscillators according to the specified parameters
  * in the RCC_OscInitTypeDef structure.
  */
  RCC_OscInitStruct.OscillatorType = RCC_OSCILLATORTYPE_HSE;
  RCC_OscInitStruct.HSEState = RCC_HSE_ON;
  RCC_OscInitStruct.PLL.PLLState = RCC_PLL_ON;
  RCC_OscInitStruct.PLL.PLLSource = RCC_PLLSOURCE_HSE;
  RCC_OscInitStruct.PLL.PLLM = 1;
  RCC_OscInitStruct.PLL.PLLN = 100;
  RCC_OscInitStruct.PLL.PLLP = 2;
  RCC_OscInitStruct.PLL.PLLQ = 4;
  RCC_OscInitStruct.PLL.PLLR = 2;
  RCC_OscInitStruct.PLL.PLLRGE = RCC_PLL1VCIRANGE_3;
  RCC_OscInitStruct.PLL.PLLVCOSEL = RCC_PLL1VCOWIDE;
  RCC_OscInitStruct.PLL.PLLFRACN = 0;
  if (HAL_RCC_OscConfig(&RCC_OscInitStruct) != HAL_OK)
  {
    Error_Handler();
  }
  /** Initializes the CPU, AHB and APB buses clocks
  */
  RCC_ClkInitStruct.ClockType = RCC_CLOCKTYPE_HCLK|RCC_CLOCKTYPE_SYSCLK
                              |RCC_CLOCKTYPE_PCLK1|RCC_CLOCKTYPE_PCLK2
                              |RCC_CLOCKTYPE_D3PCLK1|RCC_CLOCKTYPE_D1PCLK1;
  RCC_ClkInitStruct.SYSCLKSource = RCC_SYSCLKSOURCE_PLLCLK;
  RCC_ClkInitStruct.SYSCLKDivider = RCC_SYSCLK_DIV1;
  RCC_ClkInitStruct.AHBCLKDivider = RCC_HCLK_DIV2;
  RCC_ClkInitStruct.APB3CLKDivider = RCC_APB3_DIV2;
  RCC_ClkInitStruct.APB1CLKDivider = RCC_APB1_DIV2;
  RCC_ClkInitStruct.APB2CLKDivider = RCC_APB2_DIV2;
  RCC_ClkInitStruct.APB4CLKDivider = RCC_APB4_DIV2;

  if (HAL_RCC_ClockConfig(&RCC_ClkInitStruct, FLASH_LATENCY_2) != HAL_OK)
  {
    Error_Handler();
  }
  PeriphClkInitStruct.PeriphClockSelection = RCC_PERIPHCLK_USART3|RCC_PERIPHCLK_USART2
                              |RCC_PERIPHCLK_USART6|RCC_PERIPHCLK_FDCAN
                              |RCC_PERIPHCLK_USART1|RCC_PERIPHCLK_SPI1
                              |RCC_PERIPHCLK_I2C3|RCC_PERIPHCLK_ADC
                              |RCC_PERIPHCLK_I2C1;
  PeriphClkInitStruct.PLL2.PLL2M = 1;
  PeriphClkInitStruct.PLL2.PLL2N = 100;
  PeriphClkInitStruct.PLL2.PLL2P = 2;
  PeriphClkInitStruct.PLL2.PLL2Q = 10;
  PeriphClkInitStruct.PLL2.PLL2R = 2;
  PeriphClkInitStruct.PLL2.PLL2RGE = RCC_PLL2VCIRANGE_3;
  PeriphClkInitStruct.PLL2.PLL2VCOSEL = RCC_PLL2VCOWIDE;
  PeriphClkInitStruct.PLL2.PLL2FRACN = 0;
  PeriphClkInitStruct.Spi123ClockSelection = RCC_SPI123CLKSOURCE_PLL;
  PeriphClkInitStruct.FdcanClockSelection = RCC_FDCANCLKSOURCE_PLL2;
  PeriphClkInitStruct.Usart234578ClockSelection = RCC_USART234578CLKSOURCE_D2PCLK1;
  PeriphClkInitStruct.Usart16ClockSelection = RCC_USART16CLKSOURCE_D2PCLK2;
  PeriphClkInitStruct.I2c123ClockSelection = RCC_I2C123CLKSOURCE_D2PCLK1;
  PeriphClkInitStruct.AdcClockSelection = RCC_ADCCLKSOURCE_PLL2;
  if (HAL_RCCEx_PeriphCLKConfig(&PeriphClkInitStruct) != HAL_OK)
  {
    Error_Handler();
  }
}

static void MX_ADC1_Init(void)
{

  ADC_MultiModeTypeDef multimode = {0};
  ADC_ChannelConfTypeDef sConfig = {0};

  /** Common config
  */
  hadc1.Instance = ADC1;
  hadc1.Init.ClockPrescaler = ADC_CLOCK_ASYNC_DIV12;
  hadc1.Init.Resolution = ADC_RESOLUTION_12B;
  hadc1.Init.ScanConvMode = ADC_SCAN_DISABLE;
  hadc1.Init.EOCSelection = ADC_EOC_SINGLE_CONV;
  hadc1.Init.LowPowerAutoWait = DISABLE;
  hadc1.Init.ContinuousConvMode = DISABLE;
  hadc1.Init.NbrOfConversion = 1;
  hadc1.Init.DiscontinuousConvMode = DISABLE;
  hadc1.Init.ExternalTrigConv = ADC_SOFTWARE_START;
  hadc1.Init.ExternalTrigConvEdge = ADC_EXTERNALTRIGCONVEDGE_NONE;
  hadc1.Init.ConversionDataManagement = ADC_CONVERSIONDATA_DR;
  hadc1.Init.Overrun = ADC_OVR_DATA_PRESERVED;
  hadc1.Init.LeftBitShift = ADC_LEFTBITSHIFT_NONE;
  hadc1.Init.OversamplingMode = DISABLE;
  if (HAL_ADC_Init(&hadc1) != HAL_OK)
  {
    Error_Handler();
  }
  /** Configure the ADC multi-mode
  */
  multimode.Mode = ADC_MODE_INDEPENDENT;
  if (HAL_ADCEx_MultiModeConfigChannel(&hadc1, &multimode) != HAL_OK)
  {
    Error_Handler();
  }
  /** Configure Regular Channel
  */
  sConfig.Channel = ADC_CHANNEL_15;
  sConfig.Rank = ADC_REGULAR_RANK_1;
  sConfig.SamplingTime = ADC_SAMPLETIME_2CYCLES_5;
  sConfig.SingleDiff = ADC_SINGLE_ENDED;
  sConfig.OffsetNumber = ADC_OFFSET_NONE;
  sConfig.Offset = 0;
  sConfig.OffsetSignedSaturation = DISABLE;
  if (HAL_ADC_ConfigChannel(&hadc1, &sConfig) != HAL_OK)
  {
    Error_Handler();
  }

}

static void MX_FDCAN1_Init(void)
{

  hfdcan1.Instance = FDCAN1;
  hfdcan1.Init.FrameFormat = FDCAN_FRAME_FD_BRS;
  hfdcan1.Init.Mode = FDCAN_MODE_NORMAL;
  hfdcan1.Init.AutoRetransmission = ENABLE;
  hfdcan1.Init.TransmitPause = DISABLE;
  hfdcan1.Init.ProtocolException = DISABLE;
  hfdcan1.Init.NominalPrescaler = 1;
  hfdcan1.Init.NominalSyncJumpWidth = 16;
  hfdcan1.Init.NominalTimeSeg1 = 63;
  hfdcan1.Init.NominalTimeSeg2 = 16;
  hfdcan1.Init.DataPrescaler = 1;
  hfdcan1.Init.DataSyncJumpWidth = 2;
  hfdcan1.Init.DataTimeSeg1 = 7;
  hfdcan1.Init.DataTimeSeg2 = 2;
  hfdcan1.Init.MessageRAMOffset = 0;
  hfdcan1.Init.StdFiltersNbr = 1;
  hfdcan1.Init.ExtFiltersNbr = 0;
  hfdcan1.Init.RxFifo0ElmtsNbr = 1;
  hfdcan1.Init.RxFifo0ElmtSize = FDCAN_DATA_BYTES_64;
  hfdcan1.Init.RxFifo1ElmtsNbr = 0;
  hfdcan1.Init.RxFifo1ElmtSize = FDCAN_DATA_BYTES_8;
  hfdcan1.Init.RxBuffersNbr = 0;
  hfdcan1.Init.RxBufferSize = FDCAN_DATA_BYTES_8;
  hfdcan1.Init.TxEventsNbr = 0;
  hfdcan1.Init.TxBuffersNbr = 0;
  hfdcan1.Init.TxFifoQueueElmtsNbr = 10;
  hfdcan1.Init.TxFifoQueueMode = FDCAN_TX_FIFO_OPERATION;
  hfdcan1.Init.TxElmtSize = FDCAN_DATA_BYTES_64;
  if (HAL_FDCAN_Init(&hfdcan1) != HAL_OK)
  {
    Error_Handler();
  }

}

static void MX_I2C1_Init(void)
{

  hi2c1.Instance = I2C1;
  hi2c1.Init.Timing = 0x009034B6;
  hi2c1.Init.OwnAddress1 = 0;
  hi2c1.Init.AddressingMode = I2C_ADDRESSINGMODE_7BIT;
  hi2c1.Init.DualAddressMode = I2C_DUALADDRESS_DISABLE;
  hi2c1.Init.OwnAddress2 = 0;
  hi2c1.Init.OwnAddress2Masks = I2C_OA2_NOMASK;
  hi2c1.Init.GeneralCallMode = I2C_GENERALCALL_DISABLE;
  hi2c1.Init.NoStretchMode = I2C_NOSTRETCH_DISABLE;
  if (HAL_I2C_Init(&hi2c1) != HAL_OK)
  {
    Error_Handler();
  }
  /** Configure Analogue filter
  */
  if (HAL_I2CEx_ConfigAnalogFilter(&hi2c1, I2C_ANALOGFILTER_ENABLE) != HAL_OK)
  {
    Error_Handler();
  }
  /** Configure Digital filter
  */
  if (HAL_I2CEx_ConfigDigitalFilter(&hi2c1, 0) != HAL_OK)
  {
    Error_Handler();
  }

}

static void MX_I2C3_Init(void)
{

  hi2c3.Instance = I2C3;
  hi2c3.Init.Timing = 0x009034B6;
  hi2c3.Init.OwnAddress1 = 0;
  hi2c3.Init.AddressingMode = I2C_ADDRESSINGMODE_7BIT;
  hi2c3.Init.DualAddressMode = I2C_DUALADDRESS_DISABLE;
  hi2c3.Init.OwnAddress2 = 0;
  hi2c3.Init.OwnAddress2Masks = I2C_OA2_NOMASK;
  hi2c3.Init.GeneralCallMode = I2C_GENERALCALL_DISABLE;
  hi2c3.Init.NoStretchMode = I2C_NOSTRETCH_DISABLE;
  if (HAL_I2C_Init(&hi2c3) != HAL_OK)
  {
    Error_Handler();
  }
  /** Configure Analogue filter
  */
  if (HAL_I2CEx_ConfigAnalogFilter(&hi2c3, I2C_ANALOGFILTER_ENABLE) != HAL_OK)
  {
    Error_Handler();
  }
  /** Configure Digital filter
  */
  if (HAL_I2CEx_ConfigDigitalFilter(&hi2c3, 0) != HAL_OK)
  {
    Error_Handler();
  }

}

static void MX_SPI1_Init(void)
{

  /* SPI1 parameter configuration*/
  hspi1.Instance = SPI1;
  hspi1.Init.Mode = SPI_MODE_MASTER;
  hspi1.Init.Direction = SPI_DIRECTION_2LINES;
  hspi1.Init.DataSize = SPI_DATASIZE_8BIT;
  hspi1.Init.CLKPolarity = SPI_POLARITY_HIGH;
  hspi1.Init.CLKPhase = SPI_PHASE_2EDGE;
  hspi1.Init.NSS = SPI_NSS_SOFT;
  hspi1.Init.BaudRatePrescaler = SPI_BAUDRATEPRESCALER_32;
  hspi1.Init.FirstBit = SPI_FIRSTBIT_MSB;
  hspi1.Init.TIMode = SPI_TIMODE_DISABLE;
  hspi1.Init.CRCCalculation = SPI_CRCCALCULATION_DISABLE;
  hspi1.Init.CRCPolynomial = 0x0;
  hspi1.Init.NSSPMode = SPI_NSS_PULSE_ENABLE;
  hspi1.Init.NSSPolarity = SPI_NSS_POLARITY_LOW;
  hspi1.Init.FifoThreshold = SPI_FIFO_THRESHOLD_01DATA;
  hspi1.Init.TxCRCInitializationPattern = SPI_CRC_INITIALIZATION_ALL_ZERO_PATTERN;
  hspi1.Init.RxCRCInitializationPattern = SPI_CRC_INITIALIZATION_ALL_ZERO_PATTERN;
  hspi1.Init.MasterSSIdleness = SPI_MASTER_SS_IDLENESS_00CYCLE;
  hspi1.Init.MasterInterDataIdleness = SPI_MASTER_INTERDATA_IDLENESS_00CYCLE;
  hspi1.Init.MasterReceiverAutoSusp = SPI_MASTER_RX_AUTOSUSP_DISABLE;
  hspi1.Init.MasterKeepIOState = SPI_MASTER_KEEP_IO_STATE_DISABLE;
  hspi1.Init.IOSwap = SPI_IO_SWAP_DISABLE;
  if (HAL_SPI_Init(&hspi1) != HAL_OK)
  {
    Error_Handler();
  }

}

static void MX_TIM1_Init(void)
{

  TIM_ClockConfigTypeDef sClockSourceConfig = {0};
  TIM_MasterConfigTypeDef sMasterConfig = {0};
  TIM_OC_InitTypeDef sConfigOC = {0};
  TIM_BreakDeadTimeConfigTypeDef sBreakDeadTimeConfig = {0};

  htim1.Instance = TIM1;
  htim1.Init.Prescaler = 2-1;
  htim1.Init.CounterMode = TIM_COUNTERMODE_UP;
  htim1.Init.Period = 1-1;
  htim1.Init.ClockDivision = TIM_CLOCKDIVISION_DIV1;
  htim1.Init.RepetitionCounter = 0;
  htim1.Init.AutoReloadPreload = TIM_AUTORELOAD_PRELOAD_DISABLE;
  if (HAL_TIM_Base_Init(&htim1) != HAL_OK)
  {
    Error_Handler();
  }
  sClockSourceConfig.ClockSource = TIM_CLOCKSOURCE_INTERNAL;
  if (HAL_TIM_ConfigClockSource(&htim1, &sClockSourceConfig) != HAL_OK)
  {
    Error_Handler();
  }
  if (HAL_TIM_PWM_Init(&htim1) != HAL_OK)
  {
    Error_Handler();
  }
  sMasterConfig.MasterOutputTrigger = TIM_TRGO_RESET;
  sMasterConfig.MasterOutputTrigger2 = TIM_TRGO2_RESET;
  sMasterConfig.MasterSlaveMode = TIM_MASTERSLAVEMODE_DISABLE;
  if (HAL_TIMEx_MasterConfigSynchronization(&htim1, &sMasterConfig) != HAL_OK)
  {
    Error_Handler();
  }
  sConfigOC.OCMode = TIM_OCMODE_PWM1;
  sConfigOC.Pulse = 0;
  sConfigOC.OCPolarity = TIM_OCPOLARITY_HIGH;
  sConfigOC.OCNPolarity = TIM_OCNPOLARITY_HIGH;
  sConfigOC.OCFastMode = TIM_OCFAST_DISABLE;
  sConfigOC.OCIdleState = TIM_OCIDLESTATE_RESET;
  sConfigOC.OCNIdleState = TIM_OCNIDLESTATE_RESET;
  if (HAL_TIM_PWM_ConfigChannel(&htim1, &sConfigOC, TIM_CHANNEL_1) != HAL_OK)
  {
    Error_Handler();
  }
  if (HAL_TIM_PWM_ConfigChannel(&htim1, &sConfigOC, TIM_CHANNEL_2) != HAL_OK)
  {
    Error_Handler();
  }
  if (HAL_TIM_PWM_ConfigChannel(&htim1, &sConfigOC, TIM_CHANNEL_3) != HAL_OK)
  {
    Error_Handler();
  }
  if (HAL_TIM_PWM_ConfigChannel(&htim1, &sConfigOC, TIM_CHANNEL_4) != HAL_OK)
  {
    Error_Handler();
  }
  sBreakDeadTimeConfig.OffStateRunMode = TIM_OSSR_DISABLE;
  sBreakDeadTimeConfig.OffStateIDLEMode = TIM_OSSI_DISABLE;
  sBreakDeadTimeConfig.LockLevel = TIM_LOCKLEVEL_OFF;
  sBreakDeadTimeConfig.DeadTime = 0;
  sBreakDeadTimeConfig.BreakState = TIM_BREAK_DISABLE;
  sBreakDeadTimeConfig.BreakPolarity = TIM_BREAKPOLARITY_HIGH;
  sBreakDeadTimeConfig.BreakFilter = 0;
  sBreakDeadTimeConfig.Break2State = TIM_BREAK2_DISABLE;
  sBreakDeadTimeConfig.Break2Polarity = TIM_BREAK2POLARITY_HIGH;
  sBreakDeadTimeConfig.Break2Filter = 0;
  sBreakDeadTimeConfig.AutomaticOutput = TIM_AUTOMATICOUTPUT_DISABLE;
  if (HAL_TIMEx_ConfigBreakDeadTime(&htim1, &sBreakDeadTimeConfig) != HAL_OK)
  {
    Error_Handler();
  }
  HAL_TIM_MspPostInit(&htim1);

}

static void MX_TIM4_Init(void)
{

  TIM_ClockConfigTypeDef sClockSourceConfig = {0};
  TIM_MasterConfigTypeDef sMasterConfig = {0};
  TIM_OC_InitTypeDef sConfigOC = {0};

  htim4.Instance = TIM4;
  htim4.Init.Prescaler = 7;
  htim4.Init.CounterMode = TIM_COUNTERMODE_UP;
  htim4.Init.Period = 50000;
  htim4.Init.ClockDivision = TIM_CLOCKDIVISION_DIV1;
  htim4.Init.AutoReloadPreload = TIM_AUTORELOAD_PRELOAD_DISABLE;
  if (HAL_TIM_Base_Init(&htim4) != HAL_OK)
  {
    Error_Handler();
  }
  sClockSourceConfig.ClockSource = TIM_CLOCKSOURCE_INTERNAL;
  if (HAL_TIM_ConfigClockSource(&htim4, &sClockSourceConfig) != HAL_OK)
  {
    Error_Handler();
  }
  if (HAL_TIM_PWM_Init(&htim4) != HAL_OK)
  {
    Error_Handler();
  }
  sMasterConfig.MasterOutputTrigger = TIM_TRGO_RESET;
  sMasterConfig.MasterSlaveMode = TIM_MASTERSLAVEMODE_DISABLE;
  if (HAL_TIMEx_MasterConfigSynchronization(&htim4, &sMasterConfig) != HAL_OK)
  {
    Error_Handler();
  }
  sConfigOC.OCMode = TIM_OCMODE_PWM1;
  sConfigOC.Pulse = 10000;
  sConfigOC.OCPolarity = TIM_OCPOLARITY_HIGH;
  sConfigOC.OCFastMode = TIM_OCFAST_DISABLE;
  if (HAL_TIM_PWM_ConfigChannel(&htim4, &sConfigOC, TIM_CHANNEL_1) != HAL_OK)
  {
    Error_Handler();
  }
  if (HAL_TIM_PWM_ConfigChannel(&htim4, &sConfigOC, TIM_CHANNEL_2) != HAL_OK)
  {
    Error_Handler();
  }
  if (HAL_TIM_PWM_ConfigChannel(&htim4, &sConfigOC, TIM_CHANNEL_3) != HAL_OK)
  {
    Error_Handler();
  }
  if (HAL_TIM_PWM_ConfigChannel(&htim4, &sConfigOC, TIM_CHANNEL_4) != HAL_OK)
  {
    Error_Handler();
  }
  HAL_TIM_MspPostInit(&htim4);

}

static void MX_USART1_UART_Init(void)
{

  huart1.Instance = USART1;
  huart1.Init.BaudRate = 921600;
  huart1.Init.WordLength = UART_WORDLENGTH_8B;
  huart1.Init.StopBits = UART_STOPBITS_1;
  huart1.Init.Parity = UART_PARITY_NONE;
  huart1.Init.Mode = UART_MODE_TX_RX;
  huart1.Init.HwFlowCtl = UART_HWCONTROL_NONE;
  huart1.Init.OverSampling = UART_OVERSAMPLING_16;
  huart1.Init.OneBitSampling = UART_ONE_BIT_SAMPLE_DISABLE;
  huart1.Init.ClockPrescaler = UART_PRESCALER_DIV1;
  huart1.AdvancedInit.AdvFeatureInit = UART_ADVFEATURE_NO_INIT;
  if (HAL_UART_Init(&huart1) != HAL_OK)
  {
    Error_Handler();
  }
  if (HAL_UARTEx_SetTxFifoThreshold(&huart1, UART_TXFIFO_THRESHOLD_1_8) != HAL_OK)
  {
    Error_Handler();
  }
  if (HAL_UARTEx_SetRxFifoThreshold(&huart1, UART_RXFIFO_THRESHOLD_1_8) != HAL_OK)
  {
    Error_Handler();
  }
  if (HAL_UARTEx_DisableFifoMode(&huart1) != HAL_OK)
  {
    Error_Handler();
  }

}

static void MX_USART2_UART_Init(void)
{

  huart2.Instance = USART2;
  huart2.Init.BaudRate = 1000000;
  huart2.Init.WordLength = UART_WORDLENGTH_8B;
  huart2.Init.StopBits = UART_STOPBITS_1;
  huart2.Init.Parity = UART_PARITY_NONE;
  huart2.Init.Mode = UART_MODE_TX_RX;
  huart2.Init.HwFlowCtl = UART_HWCONTROL_NONE;
  huart2.Init.OverSampling = UART_OVERSAMPLING_16;
  huart2.Init.OneBitSampling = UART_ONE_BIT_SAMPLE_DISABLE;
  huart2.Init.ClockPrescaler = UART_PRESCALER_DIV1;
  huart2.AdvancedInit.AdvFeatureInit = UART_ADVFEATURE_NO_INIT;
  if (HAL_UART_Init(&huart2) != HAL_OK)
  {
    Error_Handler();
  }
  if (HAL_UARTEx_SetTxFifoThreshold(&huart2, UART_TXFIFO_THRESHOLD_1_8) != HAL_OK)
  {
    Error_Handler();
  }
  if (HAL_UARTEx_SetRxFifoThreshold(&huart2, UART_RXFIFO_THRESHOLD_1_8) != HAL_OK)
  {
    Error_Handler();
  }
  if (HAL_UARTEx_DisableFifoMode(&huart2) != HAL_OK)
  {
    Error_Handler();
  }

}

static void MX_USART3_UART_Init(void)
{

  huart3.Instance = USART3;
  if (g_uart3_driver == Uart3Driver::CRSF)
  {
    huart3.Init.BaudRate = 420000;
  }
  else
  {
    huart3.Init.BaudRate = 115200;
  }
  huart3.Init.WordLength = UART_WORDLENGTH_8B;
  huart3.Init.StopBits = UART_STOPBITS_1;
  huart3.Init.Parity = UART_PARITY_NONE;
  if (g_uart3_driver == Uart3Driver::CRSF)
  {
    huart3.Init.Mode = UART_MODE_RX;
  }
  else
  {
    huart3.Init.Mode = UART_MODE_TX_RX;
  }
  huart3.Init.HwFlowCtl = UART_HWCONTROL_NONE;
  huart3.Init.OverSampling = UART_OVERSAMPLING_16;
  huart3.Init.OneBitSampling = UART_ONE_BIT_SAMPLE_DISABLE;
  huart3.Init.ClockPrescaler = UART_PRESCALER_DIV1;
  huart3.AdvancedInit.AdvFeatureInit = UART_ADVFEATURE_NO_INIT;
  const HAL_StatusTypeDef uart_init_status =
    g_uart3_driver == Uart3Driver::CRSF ? HAL_UART_Init(&huart3) : HAL_HalfDuplex_Init(&huart3);
  if (uart_init_status != HAL_OK)
  {
    Error_Handler();
  }
  if (HAL_UARTEx_SetTxFifoThreshold(&huart3, UART_TXFIFO_THRESHOLD_1_8) != HAL_OK)
  {
    Error_Handler();
  }
  if (HAL_UARTEx_SetRxFifoThreshold(&huart3, UART_RXFIFO_THRESHOLD_1_8) != HAL_OK)
  {
    Error_Handler();
  }
  if (HAL_UARTEx_DisableFifoMode(&huart3) != HAL_OK)
  {
    Error_Handler();
  }

}

static void MX_USART6_UART_Init(void)
{

  huart6.Instance = USART6;
  huart6.Init.BaudRate = 115200;
  huart6.Init.WordLength = UART_WORDLENGTH_8B;
  huart6.Init.StopBits = UART_STOPBITS_1;
  huart6.Init.Parity = UART_PARITY_NONE;
  huart6.Init.Mode = UART_MODE_RX;
  huart6.Init.HwFlowCtl = UART_HWCONTROL_NONE;
  huart6.Init.OverSampling = UART_OVERSAMPLING_16;
  huart6.Init.OneBitSampling = UART_ONE_BIT_SAMPLE_DISABLE;
  huart6.Init.ClockPrescaler = UART_PRESCALER_DIV1;
  huart6.AdvancedInit.AdvFeatureInit = UART_ADVFEATURE_NO_INIT;
  if (HAL_UART_Init(&huart6) != HAL_OK)
  {
    Error_Handler();
  }
  if (HAL_UARTEx_SetTxFifoThreshold(&huart6, UART_TXFIFO_THRESHOLD_1_8) != HAL_OK)
  {
    Error_Handler();
  }
  if (HAL_UARTEx_SetRxFifoThreshold(&huart6, UART_RXFIFO_THRESHOLD_1_8) != HAL_OK)
  {
    Error_Handler();
  }
  if (HAL_UARTEx_DisableFifoMode(&huart6) != HAL_OK)
  {
    Error_Handler();
  }

}

static void MX_DMA_Init(void)
{

  /* DMA controller clock enable */
  __HAL_RCC_DMA1_CLK_ENABLE();
  __HAL_RCC_DMA2_CLK_ENABLE();

  /* DMA interrupt init */
  /* DMA1_Stream0_IRQn interrupt configuration */
  HAL_NVIC_SetPriority(DMA1_Stream0_IRQn, 5, 0);
  HAL_NVIC_EnableIRQ(DMA1_Stream0_IRQn);
  /* DMA1_Stream1_IRQn interrupt configuration */
  HAL_NVIC_SetPriority(DMA1_Stream1_IRQn, 5, 0);
  HAL_NVIC_EnableIRQ(DMA1_Stream1_IRQn);
  /* DMA1_Stream2_IRQn interrupt configuration */
  HAL_NVIC_SetPriority(DMA1_Stream2_IRQn, 5, 0);
  HAL_NVIC_EnableIRQ(DMA1_Stream2_IRQn);
  /* DMA1_Stream3_IRQn interrupt configuration */
  HAL_NVIC_SetPriority(DMA1_Stream3_IRQn, 5, 0);
  HAL_NVIC_EnableIRQ(DMA1_Stream3_IRQn);
  /* DMA1_Stream4_IRQn interrupt configuration */
  HAL_NVIC_SetPriority(DMA1_Stream4_IRQn, 5, 0);
  HAL_NVIC_EnableIRQ(DMA1_Stream4_IRQn);
  /* DMA2_Stream0_IRQn interrupt configuration */
  HAL_NVIC_SetPriority(DMA2_Stream0_IRQn, 5, 0);
  HAL_NVIC_EnableIRQ(DMA2_Stream0_IRQn);
  /* DMA2_Stream1_IRQn interrupt configuration */
  HAL_NVIC_SetPriority(DMA2_Stream1_IRQn, 5, 0);
  HAL_NVIC_EnableIRQ(DMA2_Stream1_IRQn);
  /* DMA2_Stream2_IRQn interrupt configuration */
  HAL_NVIC_SetPriority(DMA2_Stream2_IRQn, 5, 0);
  HAL_NVIC_EnableIRQ(DMA2_Stream2_IRQn);
  /* DMA2_Stream3_IRQn interrupt configuration */
  HAL_NVIC_SetPriority(DMA2_Stream3_IRQn, 5, 0);
  HAL_NVIC_EnableIRQ(DMA2_Stream3_IRQn);

}

static void MX_GPIO_Init(void)
{
  GPIO_InitTypeDef GPIO_InitStruct = {0};

  /* GPIO Ports Clock Enable */
  __HAL_RCC_GPIOE_CLK_ENABLE();
  __HAL_RCC_GPIOH_CLK_ENABLE();
  __HAL_RCC_GPIOC_CLK_ENABLE();
  __HAL_RCC_GPIOA_CLK_ENABLE();
  __HAL_RCC_GPIOB_CLK_ENABLE();
  __HAL_RCC_GPIOD_CLK_ENABLE();

  /*Configure GPIO pin Output Level */
  HAL_GPIO_WritePin(GPIOE, LED0_Pin|LED1_Pin|LED2_Pin|BAROCS_Pin, GPIO_PIN_RESET);

  /*Configure GPIO pin Output Level */
  HAL_GPIO_WritePin(GPIOB, IMUCS_Pin|SPI1_CS_Pin, GPIO_PIN_SET);

  /*Configure GPIO pins : LED0_Pin LED1_Pin LED2_Pin */
  GPIO_InitStruct.Pin = LED0_Pin|LED1_Pin|LED2_Pin;
  GPIO_InitStruct.Mode = GPIO_MODE_OUTPUT_OD;
  GPIO_InitStruct.Pull = GPIO_NOPULL;
  GPIO_InitStruct.Speed = GPIO_SPEED_FREQ_MEDIUM;
  HAL_GPIO_Init(GPIOE, &GPIO_InitStruct);

  /*Configure GPIO pin : IMUCS_Pin */
  GPIO_InitStruct.Pin = IMUCS_Pin;
  GPIO_InitStruct.Mode = GPIO_MODE_OUTPUT_PP;
  GPIO_InitStruct.Pull = GPIO_NOPULL;
  GPIO_InitStruct.Speed = GPIO_SPEED_FREQ_MEDIUM;
  HAL_GPIO_Init(IMUCS_GPIO_Port, &GPIO_InitStruct);

  /*Configure GPIO pin : SPI1_CS_Pin */
  GPIO_InitStruct.Pin = SPI1_CS_Pin;
  GPIO_InitStruct.Mode = GPIO_MODE_OUTPUT_PP;
  GPIO_InitStruct.Pull = GPIO_NOPULL;
  GPIO_InitStruct.Speed = GPIO_SPEED_FREQ_HIGH;
  HAL_GPIO_Init(SPI1_CS_GPIO_Port, &GPIO_InitStruct);

  /*Configure GPIO pin : BAROCS_Pin */
  GPIO_InitStruct.Pin = BAROCS_Pin;
  GPIO_InitStruct.Mode = GPIO_MODE_OUTPUT_PP;
  GPIO_InitStruct.Pull = GPIO_NOPULL;
  GPIO_InitStruct.Speed = GPIO_SPEED_FREQ_LOW;
  HAL_GPIO_Init(BAROCS_GPIO_Port, &GPIO_InitStruct);

}

void coreTaskFunc(void const * argument)
{
  /* USER CODE BEGIN 5 */
  /* start timers */
  osTimerStart(coreTaskTimerHandle, 1); // 1 ms (1kHz)
#ifdef USE_ETH
  /* init code for LWIP */
  MX_LWIP_Init();
#endif

  /* it is better to init this Node before register publisher/subscriber
     since we have to use LWIP/Ethernet after start RTOS,
     we have to first do registration before following initNode.
     Or, we can move the senser init funcs to following scope,
     which contains the HAL_Delay that effecting the RTOS tick.
     TODO: please try.
  */

  /* ros node hardware init */
#ifndef USE_ETH
  /* nh_.initNode(&huart1, &rosPubMutexHandle, &uartTxSemHandle); */
  //nh_.initNode(&huart1, &rosPubMutexHandle, NULL); // no DMA for TX
#else

  ip4_addr_t dst_addr;
  IP4_ADDR(&dst_addr,192,168,25,100);
  /* nh_.initNode(dst_addr, 12345,12345); */
#endif

  if (imu_ != nullptr)
    imu_->gyroCalib(true, IMU::GYRO_DEFAULT_CALIB_DURATION); // re-calibrate after the HAL_Delay in spine init

  osSemaphoreWait(coreTaskSemHandle, osWaitForever);

  for(;;)
    {
      osSemaphoreWait(coreTaskSemHandle, osWaitForever);

      /* Spine::send(); */
      if (imu_ != nullptr) imu_->update();
      if (g_boot_config.barometer_enabled != 0U) baro_.update();
      if (g_uart3_driver == Uart3Driver::GPS) gps_.update();
      osMutexWait(flightControlMutexHandle, osWaitForever);
      if (g_uart3_driver == Uart3Driver::CRSF)
        {
          crsf_input_.update(HAL_GetTick());
        }
      estimator_.update();
      flight_control_.update();
      osMutexRelease(flightControlMutexHandle);
      thruster_.sendCommand();

      /* Spine::update(); */

      // Workaround to handle the BUSY->TIMEOUT Error problem of ETH handler in STM32H7
      // We observe this is occasionally occur, but the ETH DMA is valid.
      if (heth.ErrorCode & HAL_ETH_ERROR_TIMEOUT)
        {
          // force to restart ETH transmit
          heth.gState = HAL_ETH_STATE_READY;
          ETH_TxDescListTypeDef *dmatxdesclist = &(heth.TxDescList);
          for (uint32_t i = 0; i < (uint32_t)ETH_TX_DESC_CNT; i++)
            {
              ETH_DMADescTypeDef *dmatxdesc = (ETH_DMADescTypeDef *)dmatxdesclist->TxDesc[i];
              CLEAR_BIT(dmatxdesc->DESC3, ETH_DMATXNDESCRF_OWN);
            }
        }
      osDelay(1);
    }

  /* USER CODE END 5 */
}

/* USER CODE BEGIN Header_communicationTaskFunc */
/**
* @brief Runs the ROS-independent XRCE-DDS client over UART1.
* @param argument: Not used
* @retval None
*/
/* USER CODE END Header_communicationTaskFunc */
void communicationTaskFunc(void const * argument)
{
  /* USER CODE BEGIN communicationTaskFunc */
  (void)argument;

  for (;;)
    {
      spinal_link_xrce_adapter_.update();
      osDelay(1);
    }
  /* USER CODE END communicationTaskFunc */
}

void idleTaskFunc(void const * argument)
{
  /* USER CODE BEGIN idleTaskFunc */
  for(;;)
  {
    // HAL_GPIO_TogglePin(LED2_GPIO_Port, LED2_Pin);
    osDelay(1000);
  }
  /* USER CODE END idleTaskFunc */
}

void imuPublishTaskFunc(void const * argument)
{
  /* USER CODE BEGIN imuPublishTaskFunc */
  (void)argument;
  osThreadTerminate(NULL);
  /* USER CODE END imuPublishTaskFunc */
}

void voltageTask(void const * argument)
{
  /* USER CODE BEGIN voltageTask */
  /* Infinite loop */
  for(;;)
  {
    if (g_boot_config.motor_output_driver == MotorOutputDriver::DRIVER_DSHOT)
    {
      (void)thruster_.updateTelemetry();
    }
    else
    {
      (void)battery_status_.update();
    }
    osDelay(VOLTAGE_CHECK_INTERVAL);
  }
  /* USER CODE END voltageTask */
}

__weak void canRxTask(void const * argument)
{
  /* USER CODE BEGIN canRxTask */
  /* Infinite loop */
  for(;;)
  {
    osDelay(1000);
  }
  /* USER CODE END canRxTask */
}

__weak void ServoTaskCallback(void const * argument)
{
  /* USER CODE BEGIN ServoTaskCallback */
  if (!servo_.connected()) {
    osThreadTerminate(NULL);
    return;
  }
  /* Infinite loop */
  for(;;)
  {
    servo_.update();
    osDelay(1);
  }
  /* USER CODE END ServoTaskCallback */
}

/* coreTaskEvokeCb function */
void coreTaskEvokeCb(void const * argument)
{
  /* USER CODE BEGIN coreTaskEvokeCb */
  if(FlashMemory::isLock()) return; // Keep flash writes isolated from control and communication work.
  // timer callback to evoke coreTask at 1KHz
  osSemaphoreRelease (coreTaskSemHandle);
  /* USER CODE END coreTaskEvokeCb */
}

/* MPU Configuration */

void MPU_Config(void)
{
  MPU_Region_InitTypeDef MPU_InitStruct = {0};

  /* Disables the MPU */
  HAL_MPU_Disable();
  /** Initializes and configures the Region and the memory to be protected
  */
  MPU_InitStruct.Enable = MPU_REGION_ENABLE;
  MPU_InitStruct.Number = MPU_REGION_NUMBER0;
  MPU_InitStruct.BaseAddress = 0x24040000;
  MPU_InitStruct.Size = MPU_REGION_SIZE_1KB;
  MPU_InitStruct.SubRegionDisable = 0x0;
  MPU_InitStruct.TypeExtField = MPU_TEX_LEVEL1;
  MPU_InitStruct.AccessPermission = MPU_REGION_FULL_ACCESS;
  MPU_InitStruct.DisableExec = MPU_INSTRUCTION_ACCESS_ENABLE;
  MPU_InitStruct.IsShareable = MPU_ACCESS_NOT_SHAREABLE;
  MPU_InitStruct.IsCacheable = MPU_ACCESS_NOT_CACHEABLE;
  MPU_InitStruct.IsBufferable = MPU_ACCESS_NOT_BUFFERABLE;

  HAL_MPU_ConfigRegion(&MPU_InitStruct);
  /** Initializes and configures the Region and the memory to be protected
  */
  MPU_InitStruct.Enable = MPU_REGION_ENABLE;
  MPU_InitStruct.Number = MPU_REGION_NUMBER1;
  MPU_InitStruct.BaseAddress = 0x24040400;
  MPU_InitStruct.Size = MPU_REGION_SIZE_16KB;
  MPU_InitStruct.SubRegionDisable = 0x0;
  MPU_InitStruct.TypeExtField = MPU_TEX_LEVEL0;
  MPU_InitStruct.AccessPermission = MPU_REGION_FULL_ACCESS;
  MPU_InitStruct.DisableExec = MPU_INSTRUCTION_ACCESS_ENABLE;
  MPU_InitStruct.IsShareable = MPU_ACCESS_SHAREABLE;
  MPU_InitStruct.IsCacheable = MPU_ACCESS_CACHEABLE;
  MPU_InitStruct.IsBufferable = MPU_ACCESS_NOT_BUFFERABLE;

  HAL_MPU_ConfigRegion(&MPU_InitStruct);
  /** Initializes and configures the Region and the memory to be protected
  */
  MPU_InitStruct.Enable = MPU_REGION_ENABLE;
  MPU_InitStruct.Number = MPU_REGION_NUMBER2;
  MPU_InitStruct.BaseAddress = 0x24044400;
  MPU_InitStruct.Size = MPU_REGION_SIZE_16KB;
  MPU_InitStruct.SubRegionDisable = 0x0;
  MPU_InitStruct.TypeExtField = MPU_TEX_LEVEL1;
  MPU_InitStruct.AccessPermission = MPU_REGION_FULL_ACCESS;
  MPU_InitStruct.DisableExec = MPU_INSTRUCTION_ACCESS_ENABLE;
  MPU_InitStruct.IsShareable = MPU_ACCESS_NOT_SHAREABLE;
  MPU_InitStruct.IsCacheable = MPU_ACCESS_NOT_CACHEABLE;
  MPU_InitStruct.IsBufferable = MPU_ACCESS_NOT_BUFFERABLE;

  HAL_MPU_ConfigRegion(&MPU_InitStruct);
  /** Initializes and configures the Region and the memory to be protected
  */
  MPU_InitStruct.Enable = MPU_REGION_ENABLE;
  MPU_InitStruct.Number = MPU_REGION_NUMBER3;
  MPU_InitStruct.BaseAddress = 0x30040000;
  MPU_InitStruct.Size = MPU_REGION_SIZE_16KB;
  MPU_InitStruct.SubRegionDisable = 0x0;
  MPU_InitStruct.TypeExtField = MPU_TEX_LEVEL1;
  MPU_InitStruct.AccessPermission = MPU_REGION_FULL_ACCESS;
  MPU_InitStruct.DisableExec = MPU_INSTRUCTION_ACCESS_ENABLE;
  MPU_InitStruct.IsShareable = MPU_ACCESS_NOT_SHAREABLE;
  MPU_InitStruct.IsCacheable = MPU_ACCESS_NOT_CACHEABLE;
  MPU_InitStruct.IsBufferable = MPU_ACCESS_NOT_BUFFERABLE;

  HAL_MPU_ConfigRegion(&MPU_InitStruct);
  /** Initializes and configures the Region and the memory to be protected
  */
  MPU_InitStruct.Enable = MPU_REGION_ENABLE;
  MPU_InitStruct.Number = MPU_REGION_NUMBER4;
  MPU_InitStruct.BaseAddress = 0x30044000;
  MPU_InitStruct.Size = MPU_REGION_SIZE_16KB;
  MPU_InitStruct.SubRegionDisable = 0x0;
  MPU_InitStruct.TypeExtField = MPU_TEX_LEVEL0;
  MPU_InitStruct.AccessPermission = MPU_REGION_FULL_ACCESS;
  MPU_InitStruct.DisableExec = MPU_INSTRUCTION_ACCESS_ENABLE;
  MPU_InitStruct.IsShareable = MPU_ACCESS_NOT_SHAREABLE;
  MPU_InitStruct.IsCacheable = MPU_ACCESS_CACHEABLE;
  MPU_InitStruct.IsBufferable = MPU_ACCESS_NOT_BUFFERABLE;

  HAL_MPU_ConfigRegion(&MPU_InitStruct);
  /** Initializes and configures the Region and the memory to be protected
  */
  MPU_InitStruct.Enable = MPU_REGION_ENABLE;
  MPU_InitStruct.Number = MPU_REGION_NUMBER5;
  MPU_InitStruct.BaseAddress = 0x30040000;
  MPU_InitStruct.Size = MPU_REGION_SIZE_256B;
  MPU_InitStruct.SubRegionDisable = 0x0;
  MPU_InitStruct.TypeExtField = MPU_TEX_LEVEL0;
  MPU_InitStruct.AccessPermission = MPU_REGION_FULL_ACCESS;
  MPU_InitStruct.DisableExec = MPU_INSTRUCTION_ACCESS_ENABLE;
  MPU_InitStruct.IsShareable = MPU_ACCESS_NOT_SHAREABLE;
  MPU_InitStruct.IsCacheable = MPU_ACCESS_NOT_CACHEABLE;
  MPU_InitStruct.IsBufferable = MPU_ACCESS_BUFFERABLE;

  HAL_MPU_ConfigRegion(&MPU_InitStruct);
  /** Initializes and configures the Region and the memory to be protected
  */
  MPU_InitStruct.Enable = MPU_REGION_ENABLE;
  MPU_InitStruct.Number = MPU_REGION_NUMBER6;
  MPU_InitStruct.BaseAddress = 0x24044800;
  MPU_InitStruct.Size = MPU_REGION_SIZE_1KB;
  MPU_InitStruct.SubRegionDisable = 0x0;
  MPU_InitStruct.TypeExtField = MPU_TEX_LEVEL1;
  MPU_InitStruct.AccessPermission = MPU_REGION_FULL_ACCESS;
  MPU_InitStruct.DisableExec = MPU_INSTRUCTION_ACCESS_ENABLE;
  MPU_InitStruct.IsShareable = MPU_ACCESS_NOT_SHAREABLE;
  MPU_InitStruct.IsCacheable = MPU_ACCESS_NOT_CACHEABLE;
  MPU_InitStruct.IsBufferable = MPU_ACCESS_NOT_BUFFERABLE;

  HAL_MPU_ConfigRegion(&MPU_InitStruct);
  /** Initializes and configures the Region and the memory to be protected
  */
  MPU_InitStruct.Enable = MPU_REGION_ENABLE;
  MPU_InitStruct.Number = MPU_REGION_NUMBER7;
  MPU_InitStruct.BaseAddress = 0x24044C00;
  MPU_InitStruct.Size = MPU_REGION_SIZE_1KB;
  MPU_InitStruct.SubRegionDisable = 0x0;
  MPU_InitStruct.TypeExtField = MPU_TEX_LEVEL1;
  MPU_InitStruct.AccessPermission = MPU_REGION_FULL_ACCESS;
  MPU_InitStruct.DisableExec = MPU_INSTRUCTION_ACCESS_ENABLE;
  MPU_InitStruct.IsShareable = MPU_ACCESS_NOT_SHAREABLE;
  MPU_InitStruct.IsCacheable = MPU_ACCESS_NOT_CACHEABLE;
  MPU_InitStruct.IsBufferable = MPU_ACCESS_NOT_BUFFERABLE;

  HAL_MPU_ConfigRegion(&MPU_InitStruct);
  /** Initializes and configures the Region and the memory to be protected
  */
  MPU_InitStruct.Enable = MPU_REGION_ENABLE;
  MPU_InitStruct.Number = MPU_REGION_NUMBER8;
  MPU_InitStruct.BaseAddress = 0x24045000;
  MPU_InitStruct.Size = MPU_REGION_SIZE_128B;
  MPU_InitStruct.SubRegionDisable = 0x0;
  MPU_InitStruct.TypeExtField = MPU_TEX_LEVEL0;
  MPU_InitStruct.AccessPermission = MPU_REGION_FULL_ACCESS;
  MPU_InitStruct.DisableExec = MPU_INSTRUCTION_ACCESS_ENABLE;
  MPU_InitStruct.IsShareable = MPU_ACCESS_NOT_SHAREABLE;
  MPU_InitStruct.IsCacheable = MPU_ACCESS_NOT_CACHEABLE;
  MPU_InitStruct.IsBufferable = MPU_ACCESS_NOT_BUFFERABLE;

  HAL_MPU_ConfigRegion(&MPU_InitStruct);
  /** Initializes and configures the Region and the memory to be protected
  */
  MPU_InitStruct.Enable = MPU_REGION_ENABLE;
  MPU_InitStruct.Number = MPU_REGION_NUMBER9;
  MPU_InitStruct.BaseAddress = 0x24045080;
  MPU_InitStruct.Size = MPU_REGION_SIZE_128B;
  MPU_InitStruct.SubRegionDisable = 0x0;
  MPU_InitStruct.TypeExtField = MPU_TEX_LEVEL0;
  MPU_InitStruct.AccessPermission = MPU_REGION_FULL_ACCESS;
  MPU_InitStruct.DisableExec = MPU_INSTRUCTION_ACCESS_ENABLE;
  MPU_InitStruct.IsShareable = MPU_ACCESS_NOT_SHAREABLE;
  MPU_InitStruct.IsCacheable = MPU_ACCESS_NOT_CACHEABLE;
  MPU_InitStruct.IsBufferable = MPU_ACCESS_NOT_BUFFERABLE;

  HAL_MPU_ConfigRegion(&MPU_InitStruct);
  /** Initializes and configures the Region and the memory to be protected
  */
  MPU_InitStruct.Enable = MPU_REGION_ENABLE;
  MPU_InitStruct.Number = MPU_REGION_NUMBER10;
  MPU_InitStruct.BaseAddress = 0x24045100;
  MPU_InitStruct.Size = MPU_REGION_SIZE_128B;
  MPU_InitStruct.SubRegionDisable = 0x0;
  MPU_InitStruct.TypeExtField = MPU_TEX_LEVEL0;
  MPU_InitStruct.AccessPermission = MPU_REGION_FULL_ACCESS;
  MPU_InitStruct.DisableExec = MPU_INSTRUCTION_ACCESS_ENABLE;
  MPU_InitStruct.IsShareable = MPU_ACCESS_NOT_SHAREABLE;
  MPU_InitStruct.IsCacheable = MPU_ACCESS_NOT_CACHEABLE;
  MPU_InitStruct.IsBufferable = MPU_ACCESS_NOT_BUFFERABLE;

  HAL_MPU_ConfigRegion(&MPU_InitStruct);
  /** Initializes and configures the Region and the memory to be protected
  */
  MPU_InitStruct.Enable = MPU_REGION_ENABLE;
  MPU_InitStruct.Number = MPU_REGION_NUMBER11;
  MPU_InitStruct.BaseAddress = 0x24045180;
  MPU_InitStruct.Size = MPU_REGION_SIZE_128B;
  MPU_InitStruct.SubRegionDisable = 0x0;
  MPU_InitStruct.TypeExtField = MPU_TEX_LEVEL0;
  MPU_InitStruct.AccessPermission = MPU_REGION_FULL_ACCESS;
  MPU_InitStruct.DisableExec = MPU_INSTRUCTION_ACCESS_ENABLE;
  MPU_InitStruct.IsShareable = MPU_ACCESS_NOT_SHAREABLE;
  MPU_InitStruct.IsCacheable = MPU_ACCESS_NOT_CACHEABLE;
  MPU_InitStruct.IsBufferable = MPU_ACCESS_NOT_BUFFERABLE;

  HAL_MPU_ConfigRegion(&MPU_InitStruct);
  /* Enables the MPU */
  HAL_MPU_Enable(MPU_PRIVILEGED_DEFAULT);

}
void HAL_TIM_PeriodElapsedCallback(TIM_HandleTypeDef *htim)
{
  if (htim->Instance == TIM12) {
    HAL_IncTick();
  }
}

void Error_Handler(void)
{
  __disable_irq();
  while (1)
  {
  }
}

/************************ (C) COPYRIGHT STMicroelectronics *****END OF FILE****/
